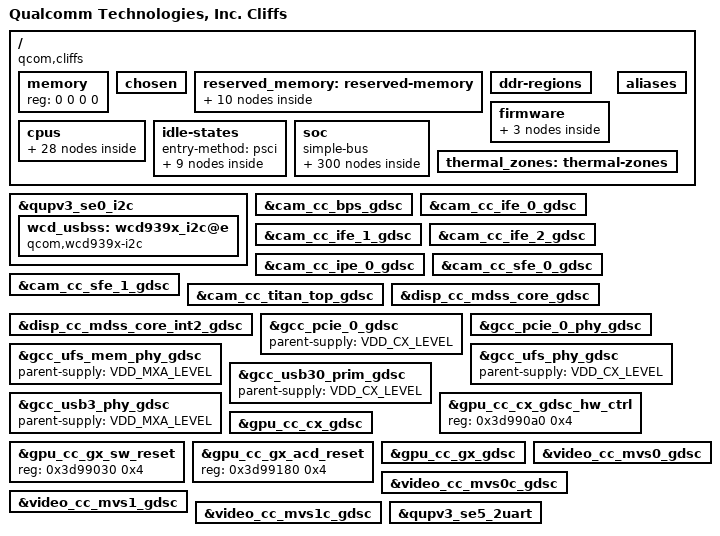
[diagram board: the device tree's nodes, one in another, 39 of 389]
#include <dt-bindings/clock/qcom,camcc-cliffs.h>
#include <dt-bindings/clock/qcom,dispcc-pineapple.h>
#include <dt-bindings/clock/qcom,gcc-cliffs.h>
#include <dt-bindings/clock/qcom,gpucc-cliffs.h>
#include <dt-bindings/clock/qcom,rpmh.h>
#include <dt-bindings/clock/qcom,tcsrcc-pineapple.h>
#include <dt-bindings/clock/qcom,videocc-pineapple.h>
#include <dt-bindings/interrupt-controller/arm-gic.h>
#include <dt-bindings/soc/qcom,ipcc.h>
#include <dt-bindings/soc/qcom,rpmh-rsc.h>
#include <dt-bindings/gpio/gpio.h>
#include <dt-bindings/interconnect/qcom,icc.h>
#include <dt-bindings/interconnect/qcom,cliffs.h>
#include <dt-bindings/spmi/spmi.h>
#include <dt-bindings/regulator/qcom,rpmh-regulator-levels.h>
#include <dt-bindings/power/qcom-aoss-qmp.h>
#include <dt-bindings/clock/qcom,aop-qmp.h>

/ {
	model = "Qualcomm Technologies, Inc. Cliffs";
	compatible = "qcom,cliffs";
	qcom,msm-id = <614 0x10000>;
	interrupt-parent = <&intc>;

	#address-cells = <2>;
	#size-cells = <2>;
	memory { device_type = "memory"; reg = <0 0 0 0>; };

	chosen: chosen {
		bootargs = "loglevel=6 kpti=0 log_buf_len=256K swiotlb=noforce loop.max_part=7 pcie_ports=compat irqaffinity=0-2 cpufreq.default_governor=performance sysctl.kernel.sched_pelt_multiplier=4 kasan=off cgroup.memory=nokmem,nosocket disable_dma32=on kernel.panic_on_rcu_stall=1 fw_devlink.strict=1 service_locator.enable=1 rcupdate.rcu_expedited=1 rcu_nocbs=0-7 no-steal-acc printk.console_no_auto_verbose=0 can.stats_timer=0 ftrace_dump_on_oops firmware_class.path=/vendor/firmware_mnt/image,/vendor/firmware_mnt/image/kiwi,/vendor/vm-system/oemvm/boot,/vendor/vm-system/trustedvm/boot,/vendor/firmware,/vendor/firmware/wlan/qca_cld/kiwi_v2 pci-msm-drv.pcie_sm_regs=0x1D07000,0x1040,0x1048,0x3000,0x1";
		stdout-path = "/soc/qcom,qupv3_0_geni_se@ac0000/qcom,qup_uart@a94000:115200n8";
	};

	reserved_memory: reserved-memory {};

	ddr-regions { };

	firmware: firmware {};

	aliases: aliases {
		serial0 = &qupv3_se5_2uart;
		hsuart0 = &qupv3_se10_4uart;
		mmc1 = &sdhc_2; /* SDC2 SD card slot */
		ufshc1 = &ufshc_mem; /* Embedded UFS Slot */
		i2c2 = &qupv3_se0_i2c;
		i2c4 = &qupv3_se11_i2c;
	};

	cpus {
		#address-cells = <2>;
		#size-cells = <0>;

		CPU0: cpu@0 {
			device_type = "cpu";
			compatible = "qcom,kryo";
			reg = <0x0 0x0>;
			enable-method = "psci";
			cpu-idle-states = <&SILVER_OFF &SILVER_RAIL_OFF>;
			power-domains = <&CPU_PD0>;
			power-domain-names = "psci";
			qcom,freq-domain = <&cpufreq_hw 0>;
			capacity-dmips-mhz = <1024>;
			dynamic-power-coefficient = <100>;
			next-level-cache = <&L2_0>;
			#cooling-cells = <2>;
			L2_0: l2-cache {
			      compatible = "arm,arch-cache";
			      cache-level = <2>;
			      next-level-cache = <&L3_0>;

				L3_0: l3-cache {
					compatible = "arm,arch-cache";
					cache-level = <3>;
				};
			};
		};

		CPU1: cpu@100 {
			device_type = "cpu";
			compatible = "qcom,kryo";
			reg = <0x0 0x100>;
			enable-method = "psci";
			cpu-idle-states = <&SILVER_OFF &SILVER_RAIL_OFF>;
			power-domains = <&CPU_PD1>;
			power-domain-names = "psci";
			qcom,freq-domain = <&cpufreq_hw 0>;
			capacity-dmips-mhz = <1024>;
			dynamic-power-coefficient = <100>;
			next-level-cache = <&L2_0>;
			#cooling-cells = <2>;
		};

		CPU2: cpu@200 {
			device_type = "cpu";
			compatible = "qcom,kryo";
			reg = <0x0 0x200>;
			enable-method = "psci";
			cpu-idle-states = <&SILVER_OFF &SILVER_RAIL_OFF>;
			power-domains = <&CPU_PD2>;
			power-domain-names = "psci";
			qcom,freq-domain = <&cpufreq_hw 0>;
			capacity-dmips-mhz = <1024>;
			dynamic-power-coefficient = <100>;
			next-level-cache = <&L2_2>;
			#cooling-cells = <2>;
			L2_2: l2-cache {
			      compatible = "arm,arch-cache";
			      cache-level = <2>;
			      next-level-cache = <&L3_0>;
			};
		};

		CPU3: cpu@300 {
			device_type = "cpu";
			compatible = "qcom,kryo";
			reg = <0x0 0x300>;
			enable-method = "psci";
			cpu-idle-states = <&GOLD_OFF &GOLD_RAIL_OFF>;
			power-domains = <&CPU_PD3>;
			power-domain-names = "psci";
			qcom,freq-domain = <&cpufreq_hw 1>;
			capacity-dmips-mhz = <1690>;
			dynamic-power-coefficient = <287>;
			next-level-cache = <&L2_3>;
			#cooling-cells = <2>;
			L2_3: l2-cache {
			      compatible = "arm,arch-cache";
			      cache-level = <2>;
			      next-level-cache = <&L3_0>;
			};
		};

		CPU4: cpu@400 {
			device_type = "cpu";
			compatible = "qcom,kryo";
			reg = <0x0 0x400>;
			enable-method = "psci";
			cpu-idle-states = <&GOLD_OFF &GOLD_RAIL_OFF>;
			power-domains = <&CPU_PD4>;
			power-domain-names = "psci";
			qcom,freq-domain = <&cpufreq_hw 1>;
			capacity-dmips-mhz = <1690>;
			dynamic-power-coefficient = <287>;
			next-level-cache = <&L2_4>;
			#cooling-cells = <2>;
			L2_4: l2-cache {
			      compatible = "arm,arch-cache";
			      cache-level = <2>;
			      next-level-cache = <&L3_0>;
			};
		};

		CPU5: cpu@500 {
			device_type = "cpu";
			compatible = "qcom,kryo";
			reg = <0x0 0x500>;
			enable-method = "psci";
			cpu-idle-states = <&GOLD_OFF &GOLD_RAIL_OFF>;
			power-domains = <&CPU_PD5>;
			power-domain-names = "psci";
			qcom,freq-domain = <&cpufreq_hw 1>;
			capacity-dmips-mhz = <1690>;
			dynamic-power-coefficient = <287>;
			next-level-cache = <&L2_5>;
			#cooling-cells = <2>;
			L2_5: l2-cache {
			      compatible = "arm,arch-cache";
			      cache-level = <2>;
			      next-level-cache = <&L3_0>;
			};
		};

		CPU6: cpu@600 {
			device_type = "cpu";
			compatible = "qcom,kryo";
			reg = <0x0 0x600>;
			enable-method = "psci";
			cpu-idle-states = <&GOLD_OFF &GOLD_RAIL_OFF>;
			power-domains = <&CPU_PD6>;
			power-domain-names = "psci";
			qcom,freq-domain = <&cpufreq_hw 1>;
			capacity-dmips-mhz = <1690>;
			dynamic-power-coefficient = <287>;
			next-level-cache = <&L2_6>;
			#cooling-cells = <2>;
			L2_6: l2-cache {
			      compatible = "arm,arch-cache";
			      cache-level = <2>;
			      next-level-cache = <&L3_0>;
			};
		};

		CPU7: cpu@700 {
			device_type = "cpu";
			compatible = "qcom,kryo";
			reg = <0x0 0x700>;
			enable-method = "psci";
			cpu-idle-states = <&GOLD_PLUS_OFF &GOLD_PLUS_RAIL_OFF>;
			power-domains = <&CPU_PD7>;
			power-domain-names = "psci";
			qcom,freq-domain = <&cpufreq_hw 2>;
			capacity-dmips-mhz = <1843>;
			dynamic-power-coefficient = <664>;
			next-level-cache = <&L2_7>;
			#cooling-cells = <2>;
			L2_7: l2-cache {
			      compatible = "arm,arch-cache";
			      cache-level = <2>;
			      next-level-cache = <&L3_0>;
			};
		};

		cpu-map {
			cluster0 {
				core0 {
					cpu = <&CPU0>;
				};

				core1 {
					cpu = <&CPU1>;
				};

				core2 {
					cpu = <&CPU2>;
				};
			};

			cluster1 {
				core0 {
					cpu = <&CPU3>;
				};

				core1 {
					cpu = <&CPU4>;
				};

				core2 {
					cpu = <&CPU5>;
				};

				core3 {
					cpu = <&CPU6>;
				};
			};

			cluster2 {
				core0 {
					cpu = <&CPU7>;
				};
			};
		};
	};

	idle-states {
		entry-method = "psci";

		SILVER_OFF: silver-c3 {  /* C3 */
			compatible = "arm,idle-state";
			idle-state-name = "pc";
			entry-latency-us = <250>;
			exit-latency-us = <900>;
			min-residency-us = <3200>;
			arm,psci-suspend-param = <0x40000003>;
			local-timer-stop;
		};

		SILVER_RAIL_OFF: silver-cluster0-c4 { /* C4 */
			compatible = "arm,idle-state";
			idle-state-name = "rail-pc";
			entry-latency-us = <550>;
			exit-latency-us = <750>;
			min-residency-us = <6700>;
			arm,psci-suspend-param = <0x40000004>;
			local-timer-stop;
		};

		GOLD_OFF: gold-c3 {  /* C3 */
			compatible = "arm,idle-state";
			idle-state-name = "pc";
			entry-latency-us = <400>;
			exit-latency-us = <1100>;
			min-residency-us = <4011>;
			arm,psci-suspend-param = <0x40000003>;
			local-timer-stop;
		};

		GOLD_RAIL_OFF: gold-cluster1-c4 { /* C4 */
			compatible = "arm,idle-state";
			idle-state-name = "rail-pc";
			entry-latency-us = <550>;
			exit-latency-us = <1050>;
			min-residency-us = <7951>;
			arm,psci-suspend-param = <0x40000004>;
			local-timer-stop;
		};

		GOLD_PLUS_OFF: gold-plus-c3 {  /* C3 */
			compatible = "arm,idle-state";
			idle-state-name = "pc";
			entry-latency-us = <450>;
			exit-latency-us = <1200>;
			min-residency-us = <6230>;
			arm,psci-suspend-param = <0x40000003>;
			local-timer-stop;
		};

		GOLD_PLUS_RAIL_OFF: gold-plus-cluster3-c4 { /* C4 */
			compatible = "arm,idle-state";
			idle-state-name = "rail-pc";
			entry-latency-us = <500>;
			exit-latency-us = <1350>;
			min-residency-us = <7480>;
			arm,psci-suspend-param = <0x40000004>;
			local-timer-stop;
		};

		CLUSTER_PWR_DN: cluster-d4 { /* D4 */
			compatible = "domain-idle-state";
			idle-state-name = "l3-off";
			entry-latency-us = <750>;
			exit-latency-us = <2350>;
			min-residency-us = <9144>;
			arm,psci-suspend-param = <0x41000044>;
		};

		CX_RET: cx-ret { /* Cx Ret */
			compatible = "domain-idle-state";
			idle-state-name = "cx-ret";
			entry-latency-us = <1561>;
			exit-latency-us = <2801>;
			min-residency-us = <8550>;
			arm,psci-suspend-param = <0x41001344>;
		};

		APSS_OFF: cluster-e3 { /* E3 */
			compatible = "domain-idle-state";
			idle-state-name = "llcc-off";
			entry-latency-us = <2800>;
			exit-latency-us = <4400>;
			min-residency-us = <10150>;
			arm,psci-suspend-param = <0x4100b344>;
		};
	};

	soc: soc { };

	thermal_zones: thermal-zones {
	};
};

#include "cliffs-coresight.dtsi"
#include "cliffs-debug.dtsi"

&soc {
	#address-cells = <1>;
	#size-cells = <1>;
	ranges = <0 0 0 0xffffffff>;
	compatible = "simple-bus";

	disp_rdump_region@d5100000 {
	};

	dsi_pll_codes {
	};

	slimbam: bamdma@6C04000 {
		compatible = "qcom,bam-v1.7.0";
		qcom,controlled-remotely;
		reg = <0x6C04000 0x20000>, <0x6C8F000 0x1000>;
		reg-names = "bam", "bam_remote_mem";
		num-channels  = <31>;
		interrupts = <0 164 IRQ_TYPE_LEVEL_HIGH>;
		#dma-cells = <1>;
		qcom,ee = <1>;
		qcom,num-ees = <2>;
	};

	slim_msm: slim@6C40000 {
		compatible = "qcom,slim-ngd-v1.5.0";
		reg = <0x6C40000 0x2C000>, <0x6C8E000 0x1000>;
		reg-names = "ctrl", "slimbus_remote_mem";
		interrupts = <0 163 IRQ_TYPE_LEVEL_HIGH>;
		qcom,apps-ch-pipes = <0x0>;
		qcom,ea-pc = <0x4f0>;
		dmas = <&slimbam 3>, <&slimbam 4>;
		dma-names = "rx", "tx";
		#address-cells = <1>;
		#size-cells = <0>;
		status = "disabled";
	};

	intc: interrupt-controller@17100000 {
		compatible = "arm,gic-v3";
		#interrupt-cells = <3>;
		interrupt-controller;
		ranges;
		#redistributor-regions = <1>;
		redistributor-stride = <0x0 0x40000>;
		reg = <0x17100000 0x10000>,	/* GICD */
		      <0x17180000 0x200000>;	/* GICR * 8 */
		interrupts = <GIC_PPI 9 IRQ_TYPE_LEVEL_HIGH>;

		#address-cells = <1>;
		#size-cells = <1>;
		gic_its: msi-controller@17140000 {
			compatible = "arm,gic-v3-its";
			msi-controller;
			#msi-cells = <1>;
			reg = <0x17140000 0x20000>;
		};
	};

	arch_timer: timer {
		compatible = "arm,armv8-timer";
		interrupts = <GIC_PPI 13 (GIC_CPU_MASK_SIMPLE(8) | IRQ_TYPE_LEVEL_LOW)>,
			     <GIC_PPI 14 (GIC_CPU_MASK_SIMPLE(8) | IRQ_TYPE_LEVEL_LOW)>,
			     <GIC_PPI 11 (GIC_CPU_MASK_SIMPLE(8) | IRQ_TYPE_LEVEL_LOW)>,
			     <GIC_PPI 12 (GIC_CPU_MASK_SIMPLE(8) | IRQ_TYPE_LEVEL_LOW)>;
		clock-frequency = <19200000>;
	};

	memtimer: timer@17420000 {
		#address-cells = <1>;
		#size-cells = <1>;
		ranges;
		compatible = "arm,armv7-timer-mem";
		reg = <0x17420000 0x1000>;
		clock-frequency = <19200000>;

		frame@17421000 {
			frame-number = <0>;
			interrupts = <GIC_SPI 8 IRQ_TYPE_LEVEL_HIGH>,
				     <GIC_SPI 6 IRQ_TYPE_LEVEL_HIGH>;
			reg = <0x17421000 0x1000>,
			      <0x17422000 0x1000>;
		};

		frame@17423000 {
			frame-number = <1>;
			interrupts = <GIC_SPI 9 IRQ_TYPE_LEVEL_HIGH>;
			reg = <0x17423000 0x1000>;
			status = "disabled";
		};

		frame@17425000 {
			frame-number = <2>;
			interrupts = <GIC_SPI 10 IRQ_TYPE_LEVEL_HIGH>;
			reg = <0x17425000 0x1000>;
			status = "disabled";
		};

		frame@17427000 {
			frame-number = <3>;
			interrupts = <GIC_SPI 11 IRQ_TYPE_LEVEL_HIGH>;
			reg = <0x17427000 0x1000>;
			status = "disabled";
		};

		frame@17429000 {
			frame-number = <4>;
			interrupts = <GIC_SPI 12 IRQ_TYPE_LEVEL_HIGH>;
			reg = <0x17429000 0x1000>;
			status = "disabled";
		};

		frame@1742b000 {
			frame-number = <5>;
			interrupts = <GIC_SPI 13 IRQ_TYPE_LEVEL_HIGH>;
			reg = <0x1742b000 0x1000>;
			status = "disabled";
		};

		frame@1742d000 {
			frame-number = <6>;
			interrupts = <GIC_SPI 14 IRQ_TYPE_LEVEL_HIGH>;
			reg = <0x1742d000 0x1000>;
			status = "disabled";
		};
	};

	apps_rsc: rsc@17a00000 {
		label = "apps_rsc";
		compatible = "qcom,rpmh-rsc";
		reg = <0x17a00000 0x10000>,
		      <0x17a10000 0x10000>,
		      <0x17a20000 0x10000>;
		reg-names = "drv-0", "drv-1", "drv-2";
		qcom,drv-count = <3>;
		interrupts = <GIC_SPI 3 IRQ_TYPE_LEVEL_HIGH>,
			     <GIC_SPI 4 IRQ_TYPE_LEVEL_HIGH>,
			     <GIC_SPI 5 IRQ_TYPE_LEVEL_HIGH>;
		power-domains = <&CLUSTER_PD>;

		apps_rsc_drv2: drv@2 {
			qcom,drv-id = <2>;
			qcom,tcs-offset = <0xd00>;
			channel@0 {
				qcom,tcs-config = <ACTIVE_TCS    3>,
						  <SLEEP_TCS     2>,
						  <WAKE_TCS      2>,
						  <CONTROL_TCS   0>,
						  <FAST_PATH_TCS 1>;
			};

			apps_bcm_voter: bcm_voter {
				compatible = "qcom,bcm-voter";
			};

			rpmhcc: clock-controller {
				compatible = "qcom,cliffs-rpmh-clk";
				#clock-cells = <1>;
			};

			dcvs_fp: qcom,dcvs-fp {
				compatible = "qcom,dcvs-fp";
				qcom,ddr-bcm-name = "MC4";
				qcom,llcc-bcm-name = "SH5";
			};
		};
	};

	pdc: interrupt-controller@b220000 {
		compatible = "qcom,cliffs-pdc", "qcom,pdc";
		reg = <0xb220000 0x10000>, <0x174000f0 0x64>;
		qcom,pdc-ranges = <0 480 94>, <94 609 31>, <125 63 1>,
				  <126 716 12>, <138 251 5>, <143 244 4>;
		#interrupt-cells = <2>;
		interrupt-parent = <&intc>;
		interrupt-controller;
	};

	pcie_pdc: pdc@b350000 {
		compatible = "qcom,cliffs-pcie-pdc", "qcom,pcie-pdc";
		reg = <0xb350000 0x20000>;
	};

	cache_cont: cache-controller@25000000 {
		label = "cache_cont";
		compatible = "qcom,cliffs-llcc", "qcom,llcc-v50";
		reg = <0x25000000 0x800000> , <0x25800000 0x200000>;
		reg-names = "llcc_base", "llcc_broadcast_base";
		interrupts = <GIC_SPI 266 IRQ_TYPE_LEVEL_HIGH>;
		cap-based-alloc-and-pwr-collapse;

		llcc-perfmon {
			compatible = "qcom,llcc-perfmon";
			clocks = <&aoss_qmp QDSS_CLK>;
			clock-names = "qdss_clk";
		};
	};

	cluster-device {
		compatible = "qcom,lpm-cluster-dev";
		power-domains = <&CLUSTER_PD>;
	};

	cam_rsc: rsc@add4000 {
		label = "cam_rsc";
		compatible = "qcom,rpmh-rsc";
		reg = <0xadd4000 0x1000>,
		      <0xadd5000 0x1000>,
		      <0xadd6000 0x1000>;
		reg-names = "drv-0", "drv-1", "drv-2";
		qcom,drv-count = <3>;
		qcom,hw-channel;
		interrupts = <GIC_SPI 368 IRQ_TYPE_LEVEL_HIGH>,
			     <GIC_SPI 369 IRQ_TYPE_LEVEL_HIGH>,
			     <GIC_SPI 370 IRQ_TYPE_LEVEL_HIGH>;
		clocks = <&camcc CAM_CC_DRV_AHB_CLK>;

		cam_rsc_drv0: drv@0 {
			qcom,drv-id = <0>;
			qcom,tcs-offset = <0x520>;
			channel@0 {
				qcom,tcs-config = <ACTIVE_TCS    0>,
						  <WAKE_TCS      1>,
						  <SLEEP_TCS     1>,
						  <CONTROL_TCS   0>,
						  <FAST_PATH_TCS 0>;
			};

			channel@1 {
				qcom,tcs-config = <ACTIVE_TCS    0>,
						  <WAKE_TCS      1>,
						  <SLEEP_TCS     1>,
						  <CONTROL_TCS   0>,
						  <FAST_PATH_TCS 0>;
			};

			cam_bcm_voter0: bcm_voter {
				compatible = "qcom,bcm-voter";
				qcom,no-amc;
			};
		};

		cam_rsc_drv1: drv@1 {
			qcom,drv-id = <1>;
			qcom,tcs-offset = <0x520>;
			channel@0 {
				qcom,tcs-config = <ACTIVE_TCS    0>,
						  <WAKE_TCS      1>,
						  <SLEEP_TCS     1>,
						  <CONTROL_TCS   0>,
						  <FAST_PATH_TCS 0>;
			};

			channel@1 {
				qcom,tcs-config = <ACTIVE_TCS    0>,
						  <WAKE_TCS      1>,
						  <SLEEP_TCS     1>,
						  <CONTROL_TCS   0>,
						  <FAST_PATH_TCS 0>;
			};

			cam_bcm_voter1: bcm_voter {
				compatible = "qcom,bcm-voter";
				qcom,no-amc;
			};
		};

		cam_rsc_drv2: drv@2 {
			qcom,drv-id = <2>;
			qcom,tcs-offset = <0x520>;
			channel@0 {
				qcom,tcs-config = <ACTIVE_TCS    0>,
						  <WAKE_TCS      1>,
						  <SLEEP_TCS     1>,
						  <CONTROL_TCS   0>,
						  <FAST_PATH_TCS 0>;
			};

			channel@1 {
				qcom,tcs-config = <ACTIVE_TCS    0>,
						  <WAKE_TCS      1>,
						  <SLEEP_TCS     1>,
						  <CONTROL_TCS   0>,
						  <FAST_PATH_TCS 0>;
			};

			cam_bcm_voter2: bcm_voter {
				compatible = "qcom,bcm-voter";
				qcom,no-amc;
			};
		};
	};

	cpuss-sleep-stats@17800054 {
		compatible = "qcom,cpuss-sleep-stats";
		reg = <0x17800054 0x4>, <0x17810054 0x4>, <0x17820054 0x4>,
		      <0x17830054 0x4>, <0x17840054 0x4>, <0x17850054 0x4>,
		      <0x17860054 0x4>, <0x17870054 0x4>, <0x178b0098 0x4>,
		      <0x178c0000 0x10000>;
		reg-names = "seq_lpm_cntr_cfg_cpu0", "seq_lpm_cntr_cfg_cpu1",
			    "seq_lpm_cntr_cfg_cpu2", "seq_lpm_cntr_cfg_cpu3",
			    "seq_lpm_cntr_cfg_cpu4", "seq_lpm_cntr_cfg_cpu5",
			    "seq_lpm_cntr_cfg_cpu6", "seq_lpm_cntr_cfg_cpu7",
			    "l3_seq_lpm_cntr_cfg", "apss_seq_mem_base";
		num-cpus = <8>;
	};

	sys-pm-vx@c320000 {
		compatible = "qcom,sys-pm-violators", "qcom,sys-pm-cliffs";
		reg = <0xc320000 0x0400>;
		qcom,qmp = <&aoss_qmp>;
	};

	disp_rsc: rsc@af20000 {
		label = "disp_rsc";
		compatible = "qcom,rpmh-rsc";
		reg = <0xaf20000 0x10000>;
		reg-names = "drv-0";
		qcom,drv-count = <1>;
		interrupts = <GIC_SPI 129 IRQ_TYPE_LEVEL_HIGH>;
		clocks = <&dispcc DISP_CC_MDSS_RSCC_AHB_CLK>;

		disp_rsc_drv0: drv@0 {
			qcom,drv-id = <0>;
			qcom,tcs-offset = <0x1c00>;
			channel@0 {
				qcom,tcs-config = <ACTIVE_TCS    0>,
						  <SLEEP_TCS     1>,
						  <WAKE_TCS      1>,
						  <CONTROL_TCS   0>,
						  <FAST_PATH_TCS 0>;
			};

			disp_bcm_voter: bcm_voter {
				compatible = "qcom,bcm-voter";
				qcom,tcs-wait = <QCOM_ICC_TAG_AMC>;
			};
		};
	};

	cam_crm: crm@add7000 {
		label = "cam_crm";
		compatible = "qcom,cam-crm";
		reg = <0xadd7000 0x2000>, <0xadd9800 0x800>, <0xadda000 0x2000>, <0xadd9000 0x800>;
		reg-names = "base", "crm_b", "crm_c", "crm_v";
		interrupts = <GIC_SPI 121 IRQ_TYPE_EDGE_RISING>;
		interrupt-names = "cam_crm";
		clocks = <&camcc CAM_CC_DRV_AHB_CLK>;
		qcom,hw-drv-ids = <0 1 2>;
		qcom,sw-drv-ids = <0>;
	};

	pcie_crm: crm@1d01000 {
		label = "pcie_crm";
		compatible = "qcom,pcie-crm";
		reg = <0x1d01000 0x3000>, <0x1d04800 0x800>, <0x1d05000 0x2000>, <0x1d04000 0x800>;
		reg-names = "base", "crm_b", "crm_c", "crm_v";
		interrupts = <GIC_SPI 248 IRQ_TYPE_EDGE_RISING>;
		interrupt-names = "pcie_crm";
		clocks = <&pcie_0_pipe_clk>;
		qcom,hw-drv-ids = <0>;
		qcom,sw-drv-ids = <0>;
	};

	sram@c3f0000 {
		compatible = "qcom,rpmh-stats-v4";
		reg = <0x0c3f0000 0x400>;
		qcom,qmp = <&aoss_qmp>;
		ss-name = "modem", "adsp", "adsp_island",
			  "cdsp", "apss", "wpss";
	};

	tlmm: pinctrl@f000000 {
		compatible = "qcom,cliffs-pinctrl";
		reg = <0x0F000000 0x1000000>;
		interrupts = <GIC_SPI 208 IRQ_TYPE_LEVEL_HIGH>;
		gpio-controller;
		#gpio-cells = <2>;
		interrupt-controller;
		#interrupt-cells = <2>;
		wakeup-parent = <&pdc>;
		qcom,gpios-reserved = <8 9 10 11 56 57 58 59 60>;
	};

	spmi_bus: spmi0_bus: qcom,spmi@c42d000 {
		compatible = "qcom,spmi-pmic-arb";
		reg = <0xc42d000 0x4000>,
		      <0xc400000 0x3000>,
		      <0xc500000 0x400000>,
		      <0xc440000 0x80000>,
		      <0xc4c0000 0x10000>;
		reg-names = "cnfg", "core", "chnls", "obsrvr", "intr";
		interrupts-extended = <&pdc 1 IRQ_TYPE_LEVEL_HIGH>;
		interrupt-names = "periph_irq";
		interrupt-controller;
		#interrupt-cells = <4>;
		#address-cells = <2>;
		#size-cells = <0>;
		cell-index = <0>;
		qcom,channel = <0>;
		qcom,ee = <0>;
		qcom,bus-id = <0>;
	};

	spmi1_bus: qcom,spmi@c432000 {
		compatible = "qcom,spmi-pmic-arb";
		reg = <0xc432000 0x4000>,
		      <0xc400000 0x3000>,
		      <0xc500000 0x400000>,
		      <0xc440000 0x80000>,
		      <0xc4d0000 0x10000>;
		reg-names = "cnfg", "core", "chnls", "obsrvr", "intr";
		interrupts-extended = <&pdc 3 IRQ_TYPE_LEVEL_HIGH>;
		interrupt-names = "periph_irq";
		interrupt-controller;
		#interrupt-cells = <4>;
		#address-cells = <2>;
		#size-cells = <0>;
		cell-index = <0>;
		qcom,channel = <0>;
		qcom,ee = <0>;
		qcom,bus-id = <1>;
		depends-on-supply = <&spmi0_bus>;
	};

	spmi0_debug_bus: qcom,spmi-debug@10b14000 {
		compatible = "qcom,spmi-pmic-arb-debug";
		reg = <0x10b14000 0x60>, <0x221c8784 0x4>;
		reg-names = "core", "fuse";
		clocks = <&aoss_qmp>;
		clock-names = "core_clk";
		qcom,fuse-enable-bit = <18>;
		#address-cells = <2>;
		#size-cells = <0>;
		depends-on-supply = <&spmi1_bus>;

		qcom,pmk8550-debug@0 {
			compatible = "qcom,spmi-pmic";
			reg = <0 SPMI_USID>;
			#address-cells = <2>;
			#size-cells = <0>;
			qcom,can-sleep;
		};

		qcom,pmxr2230-debug@1 {
			compatible = "qcom,spmi-pmic";
			reg = <1 SPMI_USID>;
			#address-cells = <2>;
			#size-cells = <0>;
			qcom,can-sleep;
		};

		qcom,pm8550vs-debug@2 {
			compatible = "qcom,spmi-pmic";
			reg = <2 SPMI_USID>;
			#address-cells = <2>;
			#size-cells = <0>;
			qcom,can-sleep;
		};

		qcom,pm8550ve-debug@3 {
			compatible = "qcom,spmi-pmic";
			reg = <3 SPMI_USID>;
			#address-cells = <2>;
			#size-cells = <0>;
			qcom,can-sleep;
		};

		qcom,pmr735a-debug@4 {
			compatible = "qcom,spmi-pmic";
			reg = <4 SPMI_USID>;
			#address-cells = <2>;
			#size-cells = <0>;
			qcom,can-sleep;
		};

		qcom,pmg1110-debug@8 {
			compatible = "qcom,spmi-pmic";
			reg = <8 SPMI_USID>;
			#address-cells = <2>;
			#size-cells = <0>;
			qcom,can-sleep;
		};

		qcom,pm8010-debug@c {
			compatible = "qcom,spmi-pmic";
			reg = <12 SPMI_USID>;
			#address-cells = <2>;
			#size-cells = <0>;
			qcom,can-sleep;
		};

		qcom,pm8010-debug@d {
			compatible = "qcom,spmi-pmic";
			reg = <13 SPMI_USID>;
			#address-cells = <2>;
			#size-cells = <0>;
			qcom,can-sleep;
		};
	};

	qcom,msm-imem@14680000 {
		compatible = "qcom,msm-imem";
		reg = <0x14680000 0x1000>;
		ranges = <0x0 0x14680000 0x1000>;
		#address-cells = <1>;
		#size-cells = <1>;

		mem_dump_table@10 {
			compatible = "qcom,msm-imem-mem_dump_table";
			reg = <0x10 0x8>;
		};

		restart_reason@65c {
			compatible = "qcom,msm-imem-restart_reason";
			reg = <0x65c 0x4>;
		};

		dload_type@1c {
			compatible = "qcom,msm-imem-dload-type";
			reg = <0x1c 0x4>;
		};

		boot_stats@6b0 {
			compatible = "qcom,msm-imem-boot_stats";
			reg = <0x6b0 0x20>;
		};

		kaslr_offset@6d0 {
			compatible = "qcom,msm-imem-kaslr_offset";
			reg = <0x6d0 0xc>;
		};

		pil@94c {
			compatible = "qcom,pil-reloc-info";
			reg = <0x94c 0xc8>;
		};

		pil@6dc {
			compatible = "qcom,msm-imem-pil-disable-timeout";
			reg = <0x6dc 0x4>;
		};

		diag_dload@c8 {
			compatible = "qcom,msm-imem-diag-dload";
			reg = <0xc8 0xc8>;
		};

		modem_dsm@c98 {
			compatible = "qcom,msm-imem-mss-dsm";
			reg = <0xc98 0x10>;
		};
	};

	dload_mode {
		compatible = "qcom,dload-mode";
	};

	mini_dump_mode {
		compatible = "qcom,minidump";
		status = "ok";
	};

	va_mini_dump {
		compatible = "qcom,va-minidump";
		memory-region = <&va_md_mem>;
		status = "ok";
	};

	cpu_pmu: cpu-pmu {
		compatible = "arm,armv8-pmuv3";
		interrupts = <GIC_PPI 7 IRQ_TYPE_LEVEL_HIGH>;
	};

	qcom,msm-cdsp-loader {
		compatible = "qcom,cdsp-loader";
		qcom,proc-img-to-load = "cdsp";
		qcom,rproc-handle = <&cdsp_pas>;
	};

	qcom,msm-adsprpc-mem {
		compatible = "qcom,msm-adsprpc-mem-region";
		memory-region = <&adsp_mem_heap>;
		restrict-access;
	};

	qcom,chd {
		compatible = "qcom,core-hang-detect";
		label = "core";
		qcom,chd-percpu-info = <&CPU0 0x17800058 0x17800060>,
					<&CPU1 0x17810058 0x17810060>,
					<&CPU2 0x17820058 0x17820060>,
					<&CPU3 0x17830058 0x17830060>,
					<&CPU4 0x17840058 0x17840060>,
					<&CPU5 0x17850058 0x17850060>,
					<&CPU6 0x17860058 0x17860060>,
					<&CPU7 0x17870058 0x17870060>;
	};

	trust_ui_vm_vblk0_ring: trust_ui_vm_vblk0_ring {
		size = <0x4000>;
		gunyah-label = <0x11>;
	};

	trust_ui_vm_vblk1_ring: trust_ui_vm_vblk1_ring {
		size = <0x4000>;
		gunyah-label = <0x10>;
	};

	trust_ui_vm_swiotlb: trust_ui_vm_swiotlb {
		size = <0x100000>;
		gunyah-label = <0x12>;
	};

	trust_ui_vm: qcom,trust_ui_vm {
		vm_name = "trustedvm";
		shared-buffers-size = <0x108000>;
		shared-buffers = <&trust_ui_vm_vblk0_ring &trust_ui_vm_vblk1_ring &trust_ui_vm_swiotlb>;
	};

	trust_ui_vm_virt_be0: trust_ui_vm_virt_be0@11 {
		qcom,vm = <&trust_ui_vm>;
		qcom,label = <0x11>;
	};

	trust_ui_vm_virt_be1: trust_ui_vm_virt_be1@10 {
		qcom,vm = <&trust_ui_vm>;
		qcom,label = <0x10>;
	};

	gh-secure-vm-loader@0 {
		compatible = "qcom,gh-secure-vm-loader";
		qcom,pas-id = <28>;
		qcom,vmid = <45>;
		qcom,firmware-name = "trustedvm";
		qcom,keep-running;
		memory-region = <&trust_ui_vm_mem &vm_comm_mem>;
		virtio-backends = <&trust_ui_vm_virt_be0 &trust_ui_vm_virt_be1>;
	};

	qcom,qrtr-gunyah-tuivm {
		compatible = "qcom,qrtr-gunyah";
		qcom,master;
		gunyah-label = <3>;
		peer-name = <2>;
	};

	gh-secure-vm-loader@2 {
		compatible = "qcom,gh-secure-vm-loader";
		qcom,pas-id = <35>;
		qcom,vmid = <50>;
		qcom,firmware-name = "cpusys_vm";
		memory-region = <&cpusys_vm_mem>;
		ext-region = <&chipinfo_mem>;
		ext-label = <0x7>;
	};

	oem_vm_vblk0_ring: oem_vm_vblk0_ring {
		size = <0x4000>;
		gunyah-label = <0x13>;
	};

	oem_vm_swiotlb: oem_vm_swiotlb {
		size = <0x100000>;
		gunyah-label = <0x14>;
	};

	oem_vm: qcom,oem_vm {
		vm_name = "oemvm";
		shared-buffers-size = <0x104000>;
		shared-buffers = <&oem_vm_vblk0_ring &oem_vm_swiotlb>;
	};

	oem_vm_virt_be0: oem_vm_virt_be0@13 {
		qcom,vm = <&oem_vm>;
		qcom,label = <0x13>;
	};

	gh-secure-vm-loader@1 {
		compatible = "qcom,gh-secure-vm-loader";
		qcom,pas-id = <34>;
		qcom,vmid = <49>;
		qcom,firmware-name = "oemvm";
		memory-region = <&oem_vm_mem &vm_comm_mem>;
		virtio-backends = <&oem_vm_virt_be0>;
	};

	qcom,qrtr-gunyah-oemvm {
		compatible = "qcom,qrtr-gunyah";
		qcom,master;
		gunyah-label = <8>;
		peer-name = <4>;
	};

	dmesg-dump {
		compatible = "qcom,dmesg-dump";
		qcom,primary-vm;
		gunyah-label = <7>;
		peer-name = <2>;
		memory-region = <&vm_comm_mem>;
		shared-buffer-size = <0x1000>;
	};

	qcom,gunyah-panic-notifier {
		compatible = "qcom,gh-panic-notifier";
		qcom,primary-vm;
		gunyah-label = <9>;
		peer-name = <2>;
		memory-region = <&vm_comm_mem>;
		shared-buffer-size = <0x1000>;
	};

	tlmm-vm-mem-access {
		compatible = "qcom,tlmm-vm-mem-access";
		qcom,master;
		tlmm-vm-gpio-list = <&tlmm 16 0 &tlmm 17 0 &tlmm 18 0 &tlmm 19 0
				     &tlmm 44 0 &tlmm 45 0 &tlmm 46 0 &tlmm 47 0
				     &tlmm 128 0 &tlmm 129 0 &tlmm 131 0 &tlmm 29 0
				     &tlmm 177 0 &tlmm 54 0 &tlmm 77 0 &tlmm 78 0>;
	};

	tlmm-vm-test {
		compatible = "qcom,tlmm-vm-test";
		qcom,master;
		tlmm-vm-gpio-list = <&tlmm 16 0 &tlmm 17 0 &tlmm 18 0 &tlmm 19 0
				     &tlmm 44 0 &tlmm 45 0 &tlmm 46 0 &tlmm 47 0
				     &tlmm 128 0 &tlmm 129 0 &tlmm 131 0 &tlmm 29 0
				     &tlmm 177 0 &tlmm 54 0 &tlmm 77 0 &tlmm 78 0>;
	};

	qcom,test-dbl-tuivm {
		compatible = "qcom,gh-dbl";
		qcom,label = <0x4>;
	};

	qcom,test-dbl-oemvm {
		compatible = "qcom,gh-dbl";
		qcom,label = <0x5>;
	};

	qcom,test-msgq-tuivm {
		compatible = "qcom,gh-msgq-test";
		gunyah-label = <4>;
		qcom,primary;
	};

	qcom,test-msgq-oemvm {
		compatible = "qcom,gh-msgq-test";
		gunyah-label = <5>;
		qcom,primary;
	};

	qcom,gh-qtimer@17425000 {
		compatible = "qcom,gh-qtmr";
		reg = <0x17425000 0x1000>;
		reg-names = "qtmr-base";
		interrupts = <GIC_SPI 10 IRQ_TYPE_LEVEL_HIGH>;
		interrupt-names = "qcom,qtmr-intr";
		qcom,primary;
	};

	clocks {
		xo_board: xo_board {
			compatible = "fixed-clock";
			clock-frequency = <76800000>;
			clock-output-names = "xo_board";
			#clock-cells = <0>;
		};

		sleep_clk: sleep_clk {
			compatible = "fixed-clock";
			clock-frequency = <32000>;
			clock-output-names = "sleep_clk";
			#clock-cells = <0>;
		};

		pcie_0_pipe_clk: pcie_0_pipe_clk {
			compatible = "fixed-clock";
			clock-frequency = <1000>;
			clock-output-names = "pcie_0_pipe_clk";
			#clock-cells = <0>;
		};

		ufs_phy_rx_symbol_0_clk: ufs_phy_rx_symbol_0_clk {
			compatible = "fixed-clock";
			clock-frequency = <1000>;
			clock-output-names = "ufs_phy_rx_symbol_0_clk";
			#clock-cells = <0>;
		};

		ufs_phy_rx_symbol_1_clk: ufs_phy_rx_symbol_1_clk {
			compatible = "fixed-clock";
			clock-frequency = <1000>;
			clock-output-names = "ufs_phy_rx_symbol_1_clk";
			#clock-cells = <0>;
		};

		ufs_phy_tx_symbol_0_clk: ufs_phy_tx_symbol_0_clk {
			compatible = "fixed-clock";
			clock-frequency = <1000>;
			clock-output-names = "ufs_phy_tx_symbol_0_clk";
			#clock-cells = <0>;
		};

		usb3_phy_wrapper_gcc_usb30_pipe_clk: usb3_phy_wrapper_gcc_usb30_pipe_clk {
			compatible = "fixed-clock";
			clock-frequency = <1000>;
			clock-output-names = "usb3_phy_wrapper_gcc_usb30_pipe_clk";
			#clock-cells = <0>;
		};
	};

	camcc_crmc: syscon@adda000 {
		compatible = "syscon";
		reg = <0xadda000 0x2000>;
	};

	camcc: clock-controller@ade0000 {
		compatible = "qcom,cliffs-camcc", "syscon";
		reg = <0xade0000 0x20000>;
		reg-name = "cc_base";
		vdd_mm-supply = <&VDD_MM_LEVEL>;
		vdd_mx-supply = <&VDD_MXA_LEVEL>;
		vdd_mxc-supply = <&VDD_MXC_LEVEL>;
		clocks = <&rpmhcc RPMH_CXO_CLK>, <&rpmhcc RPMH_CXO_CLK_A>,
			<&sleep_clk>, <&gcc GCC_CAMERA_AHB_CLK>;
		clock-names = "bi_tcxo", "bi_tcxo_ao",
			"sleep_clk", "iface";
		qcom,cam_crm-crmc = <&camcc_crmc>;
		#clock-cells = <1>;
		#reset-cells = <1>;
	};

	dispcc: clock-controller@af00000 {
		compatible = "qcom,cliffs-dispcc", "syscon";
		reg = <0xaf00000 0x20000>;
		reg-name = "cc_base";
		vdd_mm-supply = <&VDD_MM_LEVEL>;
		vdd_mxa-supply = <&VDD_MXA_LEVEL>;
		clocks = <&rpmhcc RPMH_CXO_CLK>, <&rpmhcc RPMH_CXO_CLK_A>,
			<&sleep_clk>, <&gcc GCC_DISP_AHB_CLK>;
		clock-names = "bi_tcxo", "bi_tcxo_ao",
			"sleep_clk", "iface";
		#clock-cells = <1>;
		#reset-cells = <1>;
	};

	gcc: clock-controller@100000 {
		compatible = "qcom,cliffs-gcc", "syscon";
		reg = <0x100000 0x1f4200>;
		reg-name = "cc_base";
		vdd_cx-supply = <&VDD_CX_LEVEL>;
		vdd_mx-supply = <&VDD_MXA_LEVEL>;
		clocks = <&rpmhcc RPMH_CXO_CLK>, <&pcie_0_pipe_clk>,
			<&sleep_clk>, <&ufs_phy_rx_symbol_0_clk>,
			<&ufs_phy_rx_symbol_1_clk>, <&ufs_phy_tx_symbol_0_clk>,
			<&usb3_phy_wrapper_gcc_usb30_pipe_clk>;
		clock-names = "bi_tcxo", "pcie_0_pipe_clk",
			"sleep_clk", "ufs_phy_rx_symbol_0_clk",
			"ufs_phy_rx_symbol_1_clk", "ufs_phy_tx_symbol_0_clk",
			"usb3_phy_wrapper_gcc_usb30_pipe_clk";
		#clock-cells = <1>;
		#reset-cells = <1>;
	};

	gpucc: clock-controller@3d90000 {
		compatible = "qcom,cliffs-gpucc", "syscon";
		reg = <0x3d90000 0xa000>;
		reg-name = "cc_base";
		vdd_cx-supply = <&VDD_CX_LEVEL>;
		vdd_mx-supply = <&VDD_MXA_LEVEL>;
		vdd_mxc-supply = <&VDD_MXC_LEVEL>;
		clocks = <&rpmhcc RPMH_CXO_CLK>, <&rpmhcc RPMH_CXO_CLK_A>,
			<&gcc GCC_GPU_GPLL0_CLK_SRC>, <&gcc GCC_GPU_GPLL0_DIV_CLK_SRC>;
		clock-names = "bi_tcxo", "bi_tcxo_ao",
			"gpll0_out_main", "gpll0_out_main_div";
		#clock-cells = <1>;
		#reset-cells = <1>;
	};

	tcsrcc: clock-controller@1f40000 {
		compatible = "qcom,pineapple-tcsrcc", "syscon";
		reg = <0x1f40000 0xc0000>;
		reg-name = "cc_base";
		#clock-cells = <1>;
		#reset-cells = <1>;
	};

	videocc: clock-controller@aaf0000 {
		compatible = "qcom,cliffs-videocc", "syscon";
		reg = <0xaaf0000 0x10000>;
		reg-name = "cc_base";
		vdd_mm-supply = <&VDD_MM_LEVEL>;
		vdd_mxc-supply = <&VDD_MXC_LEVEL>;
		clocks = <&rpmhcc RPMH_CXO_CLK>, <&rpmhcc RPMH_CXO_CLK_A>,
			 <&sleep_clk>, <&gcc GCC_VIDEO_AHB_CLK>;
		clock-names = "bi_tcxo", "bi_tcxo_ao",
			"sleep_clk", "iface";
		#clock-cells = <1>;
		#reset-cells = <1>;
	};

	apsscc: syscon@17a80000 {
		compatible = "syscon";
		reg = <0x17a80000 0x21000>;
	};

	mccc: syscon@240ba000 {
		compatible = "syscon";
		reg = <0x240ba000 0x54>;
	};

	debugcc: clock-controller@0 {
		compatible = "qcom,cliffs-debugcc";
		qcom,apsscc = <&apsscc>;
		qcom,camcc = <&camcc>;
		qcom,dispcc = <&dispcc>;
		qcom,gcc = <&gcc>;
		qcom,gpucc = <&gpucc>;
		qcom,videocc = <&videocc>;
		qcom,mccc = <&mccc>;
		clocks = <&rpmhcc RPMH_CXO_CLK>, <&camcc 0>,
			<&dispcc 0>, <&gcc 0>,
			<&gpucc 0>, <&videocc 0>;
		clock-names = "xo_clk_src", "camcc",
			"dispcc", "gcc",
			"gpucc", "videocc";
		#clock-cells = <1>;
	};

	cpufreq_hw: qcom,cpufreq-hw {
		compatible = "qcom,cpufreq-epss";
		reg = <0x17d91000 0x1000>, <0x17d92000 0x1000>, <0x17d93000 0x1000>;
		reg-names = "freq-domain0", "freq-domain1", "freq-domain2";
		clocks = <&rpmhcc RPMH_CXO_CLK>, <&gcc GCC_GPLL0>;
		clock-names = "xo", "alternate";
		interrupts = <GIC_SPI 30 IRQ_TYPE_LEVEL_HIGH>,
			<GIC_SPI 31 IRQ_TYPE_LEVEL_HIGH>,
			<GIC_SPI 19 IRQ_TYPE_LEVEL_HIGH>;
		interrupt-names = "dcvsh0_int", "dcvsh1_int", "dcvsh2_int";
		#freq-domain-cells = <1>;
	};

	qcom,cpufreq-hw-debug {
		compatible = "qcom,cpufreq-hw-epss-debug";
		qcom,freq-hw-domain = <&cpufreq_hw 0>, <&cpufreq_hw 1>, <&cpufreq_hw 2>;
	};

	tcsr: syscon@1fc0000 {
		compatible = "syscon";
		reg = <0x1fc0000 0x30000>;
	};

	qcom,mpm2-sleep-counter@c221000 {
		compatible = "qcom,mpm2-sleep-counter";
		reg = <0xc221000 0x1000>;
		clock-frequency = <32768>;
	};

	qcom,sps {
		compatible = "qcom,msm-sps-4k";
		qcom,pipe-attr-ee;
	};

	psci {
		compatible = "arm,psci-1.0";
		method = "smc";

		CPU_PD0: cpu-pd0 {
			#power-domain-cells = <0>;
			power-domains = <&CLUSTER_PD>;
		};

		CPU_PD1: cpu-pd1 {
			#power-domain-cells = <0>;
			power-domains = <&CLUSTER_PD>;
		};

		CPU_PD2: cpu-pd2 {
			#power-domain-cells = <0>;
			power-domains = <&CLUSTER_PD>;
		};

		CPU_PD3: cpu-pd3 {
			#power-domain-cells = <0>;
			power-domains = <&CLUSTER_PD>;
		};

		CPU_PD4: cpu-pd4 {
			#power-domain-cells = <0>;
			power-domains = <&CLUSTER_PD>;
		};

		CPU_PD5: cpu-pd5 {
			#power-domain-cells = <0>;
			power-domains = <&CLUSTER_PD>;
		};

		CPU_PD6: cpu-pd6 {
			#power-domain-cells = <0>;
			power-domains = <&CLUSTER_PD>;
		};

		CPU_PD7: cpu-pd7 {
			#power-domain-cells = <0>;
			power-domains = <&CLUSTER_PD>;
		};

		CLUSTER_PD: cluster-pd {
			#power-domain-cells = <0>;
			domain-idle-states = <&CLUSTER_PWR_DN &CX_RET &APSS_OFF>;
		};
	};

	ipcc_mproc: qcom,ipcc@406000 {
		compatible = "qcom,ipcc";
		reg = <0x406000 0x1000>;
		interrupts = <GIC_SPI 229 IRQ_TYPE_LEVEL_HIGH>;
		interrupt-controller;
		#interrupt-cells = <3>;
		#mbox-cells = <2>;
	};

	aoss_qmp: power-controller@c300000 {
		compatible = "qcom,aoss-qmp";
		reg = <0xc300000 0x400>;
		interrupt-parent = <&ipcc_mproc>;
		interrupts = <IPCC_CLIENT_AOP
				IPCC_MPROC_SIGNAL_GLINK_QMP
				IRQ_TYPE_EDGE_RISING>;
		mboxes = <&ipcc_mproc IPCC_CLIENT_AOP
				IPCC_MPROC_SIGNAL_GLINK_QMP>;
		#power-domain-cells = <1>;
		#clock-cells = <0>;
	};

	qmp_aop: qcom,qmp-aop {
		compatible = "qcom,qmp-mbox";
		qcom,qmp = <&aoss_qmp>;
		label = "aop";
		#mbox-cells = <1>;
	};

	qmp_tme: qcom,qmp-tme {
		compatible = "qcom,qmp-mbox";
		qcom,remote-pid = <14>;
		mboxes = <&ipcc_mproc IPCC_CLIENT_TME
				IPCC_MPROC_SIGNAL_GLINK_QMP>;
		mbox-names = "tme_qmp";
		interrupt-parent = <&ipcc_mproc>;
		interrupts = <IPCC_CLIENT_TME
				IPCC_MPROC_SIGNAL_GLINK_QMP
				IRQ_TYPE_EDGE_RISING>;

		label = "tme";
		qcom,early-boot;
		priority = <0>;
		mbox-desc-offset = <0x0>;
		#mbox-cells = <1>;
	};

	qcom,tmecom-qmp-client {
		compatible = "qcom,tmecom-qmp-client";
		mboxes = <&qmp_tme 0>;
		mbox-names = "tmecom";
		label = "tmecom";
		depends-on-supply = <&qmp_tme>;
	};

	qcom,smp2p-adsp {
		compatible = "qcom,smp2p";
		qcom,smem = <443>, <429>;
		interrupt-parent = <&ipcc_mproc>;
		interrupts = <IPCC_CLIENT_LPASS IPCC_MPROC_SIGNAL_SMP2P
			      IRQ_TYPE_EDGE_RISING>;
		mboxes = <&ipcc_mproc IPCC_CLIENT_LPASS
			  IPCC_MPROC_SIGNAL_SMP2P>;
		qcom,local-pid = <0>;
		qcom,remote-pid = <2>;

		adsp_smp2p_out: master-kernel {
			qcom,entry-name = "master-kernel";
			#qcom,smem-state-cells = <1>;
		};

		adsp_smp2p_in: slave-kernel {
			qcom,entry-name = "slave-kernel";
			interrupt-controller;
			#interrupt-cells = <2>;
		};

		sleepstate_smp2p_out: sleepstate-out {
			qcom,entry-name = "sleepstate";
			#qcom,smem-state-cells = <1>;
		};

		sleepstate_smp2p_in: qcom,sleepstate-in {
			qcom,entry-name = "sleepstate_see";
			interrupt-controller;
			#interrupt-cells = <2>;
		};

		smp2p_rdbg2_out: qcom,smp2p-rdbg2-out {
			qcom,entry-name = "rdbg";
			#qcom,smem-state-cells = <1>;
		};

		smp2p_rdbg2_in: qcom,smp2p-rdbg2-in {
			qcom,entry-name = "rdbg";
			interrupt-controller;
			#interrupt-cells = <2>;
		};
	};

	msm_gpu: qcom,kgsl-3d0@3d00000 { };

	mmio_sram: mmio-sram@17D09400 {
		#address-cells = <2>;
		#size-cells = <2>;
		compatible = "mmio-sram";
		reg = <0x0 0x17D09400 0x0 0x400>;
		ranges = <0x0 0x0 0x0 0x17D09400 0x0 0x400>;

		cpu_scp_lpri: scmi-shmem@0 {
			compatible = "arm,scmi-shmem";
			reg = <0x0 0x17D09400 0x0 0x400>;
		};
	};

	cpucp: qcom,cpucp@17400000 {
		#address-cells = <2>;
		#size-cells = <2>;
		compatible = "qcom,cpucp";
		reg =   <0x17400000 0x10>,
			<0x17d90000 0x2000>;
		#mbox-cells = <1>;
		interrupts = <GIC_SPI 62 IRQ_TYPE_LEVEL_HIGH>;
	};

	scmi: qcom,scmi {
		#address-cells = <1>;
		#size-cells = <0>;
		compatible = "arm,scmi";
		mboxes = <&cpucp 0>;
		mbox-names = "tx";
		shmem = <&cpu_scp_lpri>;

		scmi_memlat: protocol@80 {
			reg = <0x80>;
			#clock-cells = <1>;
		};
	};

	cpucp_log: qcom,cpucp_log@d8140000 {
		compatible = "qcom,cpucp-log";
		reg = <0xd8040000 0x10000>, <0xd8050000 0x10000>;
		mboxes = <&cpucp 1>;
	};

	qcom_c1dcvs: qcom,c1dcvs {
		compatible = "qcom,c1dcvs-v2";
	};

	qcom_cpufreq_stats: qcom,cpufreq_stats {
		compatible = "qcom,cpufreq-stats-v2";
	};

	qcom_dynpf: qcom,dynpf {
		compatible = "qcom,dynpf";
	};

	qcom,smp2p-cdsp {
		compatible = "qcom,smp2p";
		qcom,smem = <94>, <432>;
		interrupt-parent = <&ipcc_mproc>;
		interrupts = <IPCC_CLIENT_CDSP IPCC_MPROC_SIGNAL_SMP2P
			      IRQ_TYPE_EDGE_RISING>;
		mboxes = <&ipcc_mproc IPCC_CLIENT_CDSP IPCC_MPROC_SIGNAL_SMP2P>;
		qcom,local-pid = <0>;
		qcom,remote-pid = <5>;

		cdsp_smp2p_out: master-kernel {
			qcom,entry-name = "master-kernel";
			#qcom,smem-state-cells = <1>;
		};

		cdsp_smp2p_in: slave-kernel {
			qcom,entry-name = "slave-kernel";
			interrupt-controller;
			#interrupt-cells = <2>;
		};

		smp2p_rdbg5_out: qcom,smp2p-rdbg5-out {
			qcom,entry-name = "rdbg";
			#qcom,smem-state-cells = <1>;
		};

		smp2p_rdbg5_in: qcom,smp2p-rdbg5-in {
			qcom,entry-name = "rdbg";
			interrupt-controller;
			#interrupt-cells = <2>;
		};
	};

	qcom,smp2p-modem {
		compatible = "qcom,smp2p";
		qcom,smem = <435>, <428>;
		interrupt-parent = <&ipcc_mproc>;
		interrupts = <IPCC_CLIENT_MPSS IPCC_MPROC_SIGNAL_SMP2P
			      IRQ_TYPE_EDGE_RISING>;
		mboxes = <&ipcc_mproc IPCC_CLIENT_MPSS IPCC_MPROC_SIGNAL_SMP2P>;
		qcom,local-pid = <0>;
		qcom,remote-pid = <1>;

		modem_smp2p_out: master-kernel {
			qcom,entry-name = "master-kernel";
			#qcom,smem-state-cells = <1>;
		};

		modem_smp2p_in: slave-kernel {
			qcom,entry-name = "slave-kernel";
			interrupt-controller;
			#interrupt-cells = <2>;
		};

		smp2p_ipa_1_out: qcom,smp2p-ipa-1-out {
			qcom,entry-name = "ipa";
			#qcom,smem-state-cells = <1>;
		};

		/* ipa - inbound entry from mss */
		smp2p_ipa_1_in: qcom,smp2p-ipa-1-in {
			qcom,entry-name = "ipa";
			interrupt-controller;
			#interrupt-cells = <2>;
		};
	};

	qcom,smp2p_sleepstate {
		compatible = "qcom,smp2p-sleepstate";
		qcom,smem-states = <&sleepstate_smp2p_out 0>;
		interrupt-parent = <&sleepstate_smp2p_in>;
		interrupts = <0 0>;
		interrupt-names = "smp2p-sleepstate-in";
	};

	qcom,smp2p-wpss {
		compatible = "qcom,smp2p";
		qcom,smem = <617>, <616>;
		interrupt-parent = <&ipcc_mproc>;
		interrupts = <IPCC_CLIENT_WPSS IPCC_MPROC_SIGNAL_SMP2P
			IRQ_TYPE_EDGE_RISING>;
		mboxes = <&ipcc_mproc IPCC_CLIENT_WPSS IPCC_MPROC_SIGNAL_SMP2P>;
		qcom,local-pid = <0>;
		qcom,remote-pid = <13>;

		wpss_smp2p_out: master-kernel {
			qcom,entry-name = "master-kernel";
			#qcom,smem-state-cells = <1>;
		};

		wpss_smp2p_in: slave-kernel {
			qcom,entry-name = "slave-kernel";
			interrupt-controller;
			#interrupt-cells = <2>;
		};
	};

	wpss_pas: remoteproc-wpss@9bb00000 {
		compatible = "qcom,cliffs-wpss-pas";
		reg = <0x9bb00000 0x10000>;
		status = "ok";

		memory-region = <&wpss_mem>;
		firmware-name = "qca6750/wpss.mdt";

		clocks = <&rpmhcc RPMH_CXO_CLK>;
		clock-names = "xo";

		cx-supply = <&VDD_CX_LEVEL>;
		cx-uV-uA = <RPMH_REGULATOR_LEVEL_TURBO 100000>;
		mx-supply = <&VDD_MXA_LEVEL>;
		mx-uV-uA = <RPMH_REGULATOR_LEVEL_TURBO 100000>;
		reg-names = "cx","mx";

		qcom,signal-aop;
		qcom,qmp = <&aoss_qmp>;

		/* Inputs from wpss */
		interrupts-extended = <&intc GIC_SPI 200 IRQ_TYPE_EDGE_RISING>,
				      <&wpss_smp2p_in 0 0>,
				      <&wpss_smp2p_in 2 0>,
				      <&wpss_smp2p_in 1 0>,
				      <&wpss_smp2p_in 3 0>,
				      <&wpss_smp2p_in 7 0>;

		interrupt-names = "wdog",
				   "fatal",
				   "handover",
				   "ready",
				   "stop-ack",
				   "shutdown-ack";

		/* Outputs to wpss */
		qcom,smem-states = <&wpss_smp2p_out 0>;
		qcom,smem-state-names = "stop";

		glink-edge {
			qcom,remote-pid = <13>;
			transport = "smem";
			mboxes = <&ipcc_mproc IPCC_CLIENT_WPSS
				  IPCC_MPROC_SIGNAL_GLINK_QMP>;
			mbox-names = "wpss_smem";
			interrupt-parent = <&ipcc_mproc>;
			interrupts = <IPCC_CLIENT_WPSS
					  IPCC_MPROC_SIGNAL_GLINK_QMP
					  IRQ_TYPE_EDGE_RISING>;

			label = "wpss";
			qcom,glink-label = "wpss";

			qcom,wpss_qrtr {
				qcom,glink-channels = "IPCRTR";
				qcom,intents = <0x800  5
						0x2000 3
						0x4400 2>;
			};

		};
	};

	adsp_sleepmon: adsp-sleepmon {
		compatible = "qcom,adsp-sleepmon";
		qcom,wait_time_lpm = <45>;
		qcom,rproc-handle = <&adsp_pas>;
	};

	adsp_pas: remoteproc-adsp@03000000 {
		compatible = "qcom,cliffs-adsp-pas";
		reg = <0x03000000 0x10000>;
		status = "ok";

		cx-supply = <&VDD_LPI_CX_LEVEL>;
		cx-uV-uA = <RPMH_REGULATOR_LEVEL_TURBO 0>;
		mx-supply = <&VDD_LPI_MX_LEVEL>;
		mx-uV-uA = <RPMH_REGULATOR_LEVEL_TURBO 0>;
		reg-names = "cx", "mx";

		clocks = <&rpmhcc RPMH_CXO_CLK>;
		clock-names = "xo";

		qcom,signal-aop;
		qcom,qmp = <&aoss_qmp>;

		interconnects = <&lpass_lpicx_noc MASTER_LPASS_PROC &mc_virt SLAVE_EBI1>,
				<&aggre2_noc MASTER_CRYPTO &mc_virt SLAVE_EBI1>;
		interconnect-names = "rproc_ddr", "crypto_ddr";

		memory-region = <&adspslpi_mem &q6_adsp_dtb_mem>;

		/* Inputs from ssc */
		interrupts-extended = <&pdc 6 IRQ_TYPE_EDGE_RISING>,
					<&adsp_smp2p_in 0 0>,
					<&adsp_smp2p_in 2 0>,
					<&adsp_smp2p_in 1 0>,
					<&adsp_smp2p_in 3 0>;

		interrupt-names = "wdog",
				"fatal",
				"handover",
				"ready",
				"stop-ack";

		/* Outputs to turing */
		qcom,smem-states = <&adsp_smp2p_out 0>;
		qcom,smem-state-names = "stop";

		glink_edge: glink-edge {
			qcom,remote-pid = <2>;
			transport = "smem";
			mboxes = <&ipcc_mproc IPCC_CLIENT_LPASS
				  IPCC_MPROC_SIGNAL_GLINK_QMP>;
			mbox-names = "adsp_smem";
			interrupt-parent = <&ipcc_mproc>;
			interrupts = <IPCC_CLIENT_LPASS
				      IPCC_MPROC_SIGNAL_GLINK_QMP
				      IRQ_TYPE_EDGE_RISING>;

			label = "adsp";
			qcom,glink-label = "lpass";

			qcom,adsp_qrtr {
				qcom,glink-channels = "IPCRTR";
				qcom,intents = <0x800  5
						0x2000 3
						0x4400 2>;

				qcom,no-wake-svc = <0x190>;
			};

			qcom,pmic_glink_rpmsg {
				qcom,glink-channels = "PMIC_RTR_ADSP_APPS";
			};

			qcom,pmic_glink_log_rpmsg {
				qcom,glink-channels = "PMIC_LOGS_ADSP_APPS";
				qcom,intents = <0x800 5
						0xc00 3
						0x2000 1>;
			};

			qcom,msm_fastrpc_rpmsg {
				compatible = "qcom,msm-fastrpc-rpmsg";
				qcom,glink-channels = "fastrpcglink-apps-dsp";
				qcom,intents = <0x64 64>;
			};
		};
	};

	modem_pas: remoteproc-mss@04080000 {
		compatible = "qcom,cliffs-modem-pas";
		reg = <0x4080000 0x10000>;
		status = "ok";

		clocks = <&rpmhcc RPMH_CXO_CLK>;
		clock-names = "xo";

		cx-supply = <&VDD_CX_LEVEL>;
		cx-uV-uA = <RPMH_REGULATOR_LEVEL_TURBO 100000>;
		mx-supply = <&VDD_MODEM_LEVEL>;
		mx-uV-uA = <RPMH_REGULATOR_LEVEL_NOM_L1 100000>;
		reg-names = "cx", "mx";

		qcom,signal-aop;
		qcom,qmp = <&aoss_qmp>;

		interconnects = <&mc_virt MASTER_LLCC &mc_virt SLAVE_EBI1>,
				<&aggre2_noc MASTER_CRYPTO &mc_virt SLAVE_EBI1>;
		interconnect-names = "rproc_ddr", "crypto_ddr";

		memory-region = <&mpss_mem &q6_mpss_dtb_mem &system_cma>;
		mpss_dsm_mem_reg = <&dsm_partition_1_mem>;

		/* Inputs from mss */
		interrupts-extended = <&intc GIC_SPI 264 IRQ_TYPE_EDGE_RISING>,
					<&modem_smp2p_in 0 0>,
					<&modem_smp2p_in 2 0>,
					<&modem_smp2p_in 1 0>,
					<&modem_smp2p_in 3 0>,
					<&modem_smp2p_in 7 0>;

		interrupt-names = "wdog",
				"fatal",
				"handover",
				"ready",
				"stop-ack",
				"shutdown-ack";

		/* Outputs to mss */
		qcom,smem-states = <&modem_smp2p_out 0>;
		qcom,smem-state-names = "stop";

		glink-edge {
			qcom,remote-pid = <1>;
			transport = "smem";
			mboxes = <&ipcc_mproc IPCC_CLIENT_MPSS
				  IPCC_MPROC_SIGNAL_GLINK_QMP>;
			mbox-names = "mpss_smem";
			interrupt-parent = <&ipcc_mproc>;
			interrupts = <IPCC_CLIENT_MPSS
				      IPCC_MPROC_SIGNAL_GLINK_QMP
				      IRQ_TYPE_EDGE_RISING>;

			label = "modem";
			qcom,glink-label = "mpss";

			qcom,modem_qrtr {
				qcom,glink-channels = "IPCRTR";
				qcom,low-latency;
				qcom,intents = <0x800  5
						0x2000 3
						0x4400 2>;
			};

			qcom,modem_ds {
				qcom,glink-channels = "DS";
				qcom,intents = <0x4000 0x2>;
			};
		};
	};

	cdsp_pas: remoteproc-cdsp@32300000 {
		compatible = "qcom,cliffs-cdsp-pas";
		reg = <0x32300000 0x10000>;
		status = "ok";

		cx-supply = <&VDD_CX_LEVEL>;
		cx-uV-uA = <RPMH_REGULATOR_LEVEL_TURBO 100000>;
		mx-supply = <&VDD_MXC_LEVEL>;
		mx-uV-uA = <RPMH_REGULATOR_LEVEL_TURBO 100000>;
		nsp-supply = <&VDD_NSP_LEVEL>;
		nsp-uV-uA = <RPMH_REGULATOR_LEVEL_TURBO 100000>;
		reg-names = "cx","mx","nsp";

		memory-region = <&cdsp_mem &q6_cdsp_dtb_mem>;
		global-sync-mem-reg = <&global_sync_mem>;

		clocks = <&rpmhcc RPMH_CXO_CLK>;
		clock-names = "xo";

		qcom,signal-aop;
		qcom,qmp = <&aoss_qmp>;

		interconnects = <&nsp_noc MASTER_CDSP_PROC &mc_virt SLAVE_EBI1>,
				<&aggre2_noc MASTER_CRYPTO &mc_virt SLAVE_EBI1>;
		interconnect-names = "rproc_ddr", "crypto_ddr";

		/* Inputs from turing */
		interrupts-extended = <&intc GIC_SPI 578 IRQ_TYPE_EDGE_RISING>,
					<&cdsp_smp2p_in 0 0>,
					<&cdsp_smp2p_in 2 0>,
					<&cdsp_smp2p_in 1 0>,
					<&cdsp_smp2p_in 3 0>;

		interrupt-names = "wdog",
				"fatal",
				"handover",
				"ready",
				"stop-ack";

		/* Outputs to turing */
		qcom,smem-states = <&cdsp_smp2p_out 0>;
		qcom,smem-state-names = "stop";

		glink-edge {
			qcom,remote-pid = <5>;
			transport = "smem";
			mboxes = <&ipcc_mproc IPCC_CLIENT_CDSP
				  IPCC_MPROC_SIGNAL_GLINK_QMP>;
			mbox-names = "cdsp_smem";
			interrupt-parent = <&ipcc_mproc>;
			interrupts = <IPCC_CLIENT_CDSP
				      IPCC_MPROC_SIGNAL_GLINK_QMP
				      IRQ_TYPE_EDGE_RISING>;

			label = "cdsp";
			qcom,glink-label = "cdsp";

			qcom,cdsp_qrtr {
				qcom,glink-channels = "IPCRTR";
				qcom,intents = <0x800  5
						0x2000 3
						0x4400 2>;
			};

			qcom,msm_cdsprm_rpmsg {
				compatible = "qcom,msm-cdsprm-rpmsg";
				qcom,glink-channels = "cdsprmglink-apps-dsp";
				qcom,intents = <0x20 12
						0xF00 12>;

				msm_cdsp_rm: qcom,msm_cdsp_rm {
					compatible = "qcom,msm-cdsp-rm";
					qcom,qos-cores = <0 1 2>;
					qcom,qos-latency-us = <70>;
					qcom,qos-maxhold-ms = <20>;
				};
			};

			qcom,msm_fastrpc_rpmsg {
				compatible = "qcom,msm-fastrpc-rpmsg";
				qcom,glink-channels = "fastrpcglink-apps-dsp";
				qcom,intents = <0x64 64>;
			};
		};
	};

	qcom,glinkpkt {
		compatible = "qcom,glinkpkt";

		qcom,glinkpkt-at-mdm0 {
			qcom,glinkpkt-edge = "mpss";
			qcom,glinkpkt-ch-name = "DS";
			qcom,glinkpkt-dev-name = "at_mdm0";
		};

		qcom,glinkpkt-apr-apps2 {
			qcom,glinkpkt-edge = "adsp";
			qcom,glinkpkt-ch-name = "apr_apps2";
			qcom,glinkpkt-dev-name = "apr_apps2";
		};

		qcom,glinkpkt-data40-cntl {
			qcom,glinkpkt-edge = "mpss";
			qcom,glinkpkt-ch-name = "DATA40_CNTL";
			qcom,glinkpkt-dev-name = "smdcntl8";
		};

		qcom,glinkpkt-data1 {
			qcom,glinkpkt-edge = "mpss";
			qcom,glinkpkt-ch-name = "DATA1";
			qcom,glinkpkt-dev-name = "smd7";
		};

		qcom,glinkpkt-data4 {
			qcom,glinkpkt-edge = "mpss";
			qcom,glinkpkt-ch-name = "DATA4";
			qcom,glinkpkt-dev-name = "smd8";
		};

		qcom,glinkpkt-data11 {
			qcom,glinkpkt-edge = "mpss";
			qcom,glinkpkt-ch-name = "DATA11";
			qcom,glinkpkt-dev-name = "smd11";
		};

		qcom,glinkpkt-qmc-dma {
			qcom,glinkpkt-edge = "mpss";
			qcom,glinkpkt-ch-name = "QMC_DMA_LINE";
			qcom,glinkpkt-dev-name = "qmc_dma";
			qcom,glinkpkt-enable-ch-close;
		};

		qcom,glinkpkt-qmc-cma {
			qcom,glinkpkt-edge = "mpss";
			qcom,glinkpkt-ch-name = "QMC_CMA_LINE";
			qcom,glinkpkt-dev-name = "qmc_cma";
			qcom,glinkpkt-enable-ch-close;
		};
	};

	qcom,glink {
		compatible = "qcom,glink";
	};

	google,debug-kinfo {
		compatible = "google,debug-kinfo";
		memory-region = <&kinfo_mem>;
	};

	vendor_hooks: qcom,cpu-vendor-hooks {
		compatible = "qcom,cpu-vendor-hooks";
	};

	logbuf: qcom,logbuf-vendor-hooks {
		compatible = "qcom,logbuf-vendor-hooks";
	};

	tcsr_mutex_block: syscon@1f40000 {
		compatible = "syscon";
		reg = <0x1f40000 0x20000>;
	};

	tcsr_mutex: hwlock {
		compatible = "qcom,tcsr-mutex";
		syscon = <&tcsr_mutex_block 0 0x1000>;
		#hwlock-cells = <1>;
	};

	qcom_tzlog: tz-log@14680720 {
		compatible = "qcom,tz-log";
		reg = <0x14680720 0x3000>;
		qcom,hyplog-enabled;
		hyplog-address-offset = <0x410>;
		hyplog-size-offset = <0x414>;
		tmecrashdump-address-offset = <0x81CA0000>;
	};

	qcom_qseecom: qseecom@c1700000 {
		compatible = "qcom,qseecom";
		memory-region = <&qseecom_mem>;
		qseecom_mem = <&qseecom_mem>;
		qseecom_ta_mem = <&qseecom_ta_mem>;
		qcom,no-user-contig-mem-support;
		qcom,hlos-num-ce-hw-instances = <1>;
		qcom,hlos-ce-hw-instance = <0>;
		qcom,qsee-ce-hw-instance = <0>;
		qcom,disk-encrypt-pipe-pair = <2>;
		qcom,no-clock-support;
		qcom,appsbl-qseecom-support;
		qcom,commonlib64-loaded-by-uefi;
		qcom,qsee-reentrancy-support = <2>;
	};

	qcom_cedev: qcedev@1de0000 {
		compatible = "qcom,qcedev";
		reg = <0x1de0000 0x20000>,
			<0x1dc4000 0x28000>;
		reg-names = "crypto-base","crypto-bam-base";
		interrupts = <GIC_SPI 272 IRQ_TYPE_LEVEL_HIGH>;
		qcom,bam-pipe-pair = <2>;
		qcom,offload-ops-support;
		qcom,bam-pipe-offload-cpb-hlos = <1>;
		qcom,bam-pipe-offload-hlos-cpb = <3>;
		qcom,bam-pipe-offload-hlos-cpb-1 = <8>;
		qcom,bam-pipe-offload-hlos-hlos = <4>;
		qcom,bam-pipe-offload-hlos-hlos-1 = <9>;
		qcom,ce-hw-instance = <0>;
		qcom,ce-device = <0>;
		qcom,ce-hw-shared;
		qcom,bam-ee = <0>;
		qcom,smmu-s1-enable;
		qcom,no-clock-support;
		interconnect-names = "data_path";
		interconnects = <&aggre2_noc MASTER_CRYPTO &mc_virt SLAVE_EBI1>;
		iommus = <&apps_smmu 0x0480 0x0>,
			<&apps_smmu 0x0481 0x0>;
		qcom,iommu-dma = "atomic";
		dma-coherent;

		qcom_cedev_ns_cb {
			compatible = "qcom,qcedev,context-bank";
			label = "ns_context";
			iommus = <&apps_smmu 0x0481 0x0>;
			dma-coherent;
		};

		qcom_cedev_s_cb {
			compatible = "qcom,qcedev,context-bank";
			label = "secure_context";
			iommus = <&apps_smmu 0x0483 0x0>;
			qcom,iommu-vmid = <0x9>;
			qcom,secure-context-bank;
			dma-coherent;
		};
	};

	qcom_rng: qrng@10c3000 {
		compatible = "qcom,msm-rng";
		reg = <0x10c3000 0x1000>;
		qcom,no-qrng-config;
		qcom,no-clock-support;
	};

	gic-interrupt-router {
		compatible = "qcom,gic-intr-routing";
		/* keep silver core only to avoid wakeup of gold cores */
		qcom,gic-class0-cpus = <0 1 2>;
		/* keep gold and gold+ cores in class1 */
		qcom,gic-class1-cpus = <3 4 5 6 7>;
	};

	qfprom: qfprom@221c8000 {
		compatible = "qcom,cliffs-qfprom", "qcom,qfprom";
		reg = <0x221c8000 0x1000>;
		#address-cells = <1>;
		#size-cells = <1>;
		read-only;
		ranges;

		feat_conf6: feat_conf6@0118 {
			reg = <0x0118 0x4>;
		};
	};

	qfprom_sys: qfprom@0 {
		compatible = "qcom,qfprom-sys";

		nvmem-cells = <&feat_conf6>;
		nvmem-cell-names = "feat_conf6";
	};

	sdhc2_opp_table: sdhc2-opp-table {
		compatible = "operating-points-v2";

		opp-100000000 {
			opp-hz = /bits/ 64 <100000000>;
			opp-peak-kBps = <160000 100000>;
			opp-avg-kBps = <50000 0>;
		};

		opp-202000000 {
			opp-hz = /bits/ 64 <202000000>;
			opp-peak-kBps = <200000 120000>;
			opp-avg-kBps = <104000 0>;
		};
	};

	sdhc_2: sdhci@8804000 {
		status = "disabled";

		compatible = "qcom,sdhci-msm-v5";

		reg = <0x08804000 0x1000>;
		reg-names = "hc";

		interrupts = <GIC_SPI 207 IRQ_TYPE_LEVEL_HIGH>,
				<GIC_SPI 223 IRQ_TYPE_LEVEL_HIGH>;
		interrupt-names = "hc_irq", "pwr_irq";

		bus-width = <4>;
		no-sdio;
		no-mmc;
		qcom,restore-after-cx-collapse;

		qcom,uses_level_shifter;

		resets = <&gcc GCC_SDCC2_BCR>;
		reset-names = "core_reset";

		clocks = <&gcc GCC_SDCC2_AHB_CLK>,
			<&gcc GCC_SDCC2_APPS_CLK>;
		clock-names = "iface", "core";

		/*
		 * DLL HSR settings. Refer go/hsr - <Target> DLL settings.
		 * Note that the DLL_CONFIG_2 value is not passed from the
		 * device tree, but it is calculated in the driver.
		 */
		qcom,dll-hsr-list = <0x0007442C 0x0 0x10
					0x090106C0 0x80040868>;

		iommus = <&apps_smmu 0x140 0x0>;
		dma-coherent;
		qcom,iommu-dma = "fastmap";

		interconnects = <&aggre1_noc MASTER_SDCC_2 &mc_virt SLAVE_EBI1>,
			      <&gem_noc MASTER_APPSS_PROC &cnoc_cfg
			      SLAVE_SDCC_2>;
		interconnect-names = "sdhc-ddr","cpu-sdhc";
		operating-points-v2 = <&sdhc2_opp_table>;

		qos0 {
			mask = <0xf8>;
			vote = <44>;
		};

		qos1 {
			mask = <0x07>;
			vote = <44>;
		};
	};

	ufsphy_mem: ufsphy_mem@1d80000 {
		reg = <0x1d80000 0x2000>;
		reg-names = "phy_mem";
		#phy-cells = <0>;

		lanes-per-direction = <2>;
		clock-names = "ref_clk_src",
			"ref_aux_clk", "qref_clk",
			"rx_sym0_mux_clk", "rx_sym1_mux_clk", "tx_sym0_mux_clk",
			"rx_sym0_phy_clk", "rx_sym1_phy_clk", "tx_sym0_phy_clk";
		clocks =<&rpmhcc RPMH_CXO_PAD_CLK>,
			<&gcc GCC_UFS_PHY_PHY_AUX_CLK>,
			<&tcsrcc TCSR_UFS_CLKREF_EN>,
			<&gcc GCC_UFS_PHY_RX_SYMBOL_0_CLK_SRC>,
			<&gcc GCC_UFS_PHY_RX_SYMBOL_1_CLK_SRC>,
			<&gcc GCC_UFS_PHY_TX_SYMBOL_0_CLK_SRC>,
			<&ufs_phy_rx_symbol_0_clk>,
			<&ufs_phy_rx_symbol_1_clk>,
			<&ufs_phy_tx_symbol_0_clk>;
		resets = <&ufshc_mem 0>;
		status = "disabled";
	};

	ice_cfg: shared_ice {
		alg1 {
			alg-name = "alg1";
			rx-alloc-percent = <60>;
			status = "disabled";
		};

		alg2 {
			alg-name = "alg2";
			status = "disabled";

		};

		alg3 {
			alg-name = "alg3";
			num-core = <28 28 15 13>;
			status = "ok";
		};
	};

	ufshc_mem: ufshc@1d84000 {
		compatible = "qcom,ufshc";
		reg = <0x1d84000 0x3000>,
			<0x1d88000 0x8000>,
			<0x1d90000 0x9000>,
			<0x1da5000 0x2000>, <0x1da4000 0x10>;
		reg-names = "ufs_mem", "ufs_ice", "ufs_ice_hwkm", "mcq_sqd", "mcq_vs";
		interrupts = <GIC_SPI 265 IRQ_TYPE_LEVEL_HIGH>;
		phys = <&ufsphy_mem>;
		phy-names = "ufsphy";
		#reset-cells = <1>;

		qcom,prime-mask = <0x80>;
		qcom,silver-mask = <0x07>;
		qcom,esi-affinity-mask = <0xf8>;

		lanes-per-direction = <2>;
		clock-names =
			"core_clk",
			"bus_aggr_clk",
			"iface_clk",
			"core_clk_unipro",
			"core_clk_ice",
			"ref_clk",
			"tx_lane0_sync_clk",
			"rx_lane0_sync_clk",
			"rx_lane1_sync_clk";
		clocks =
			<&gcc GCC_UFS_PHY_AXI_CLK>,
			<&gcc GCC_AGGRE_UFS_PHY_AXI_CLK>,
			<&gcc GCC_UFS_PHY_AHB_CLK>,
			<&gcc GCC_UFS_PHY_UNIPRO_CORE_CLK>,
			<&gcc GCC_UFS_PHY_ICE_CORE_CLK>,
			<&rpmhcc RPMH_LN_BB_CLK3>,
			<&gcc GCC_UFS_PHY_TX_SYMBOL_0_CLK>,
			<&gcc GCC_UFS_PHY_RX_SYMBOL_0_CLK>,
			<&gcc GCC_UFS_PHY_RX_SYMBOL_1_CLK>;
		freq-table-hz =
			<100000000 403000000>,
			<0 0>,
			<0 0>,
			<100000000 403000000>,
			<100000000 403000000>,
			<0 0>,
			<0 0>,
			<0 0>,
			<0 0>;

		interconnects = <&aggre1_noc MASTER_UFS_MEM &mc_virt SLAVE_EBI1>,
			<&gem_noc MASTER_APPSS_PROC &cnoc_cfg SLAVE_UFS_MEM_CFG>;
		interconnect-names = "ufs-ddr", "cpu-ufs";

		qcom,ufs-bus-bw,name = "ufshc_mem";
		qcom,ufs-bus-bw,num-cases = <30>;
		qcom,ufs-bus-bw,num-paths = <2>;
		qcom,ufs-bus-bw,vectors-KBps =
		/*
		 * During HS G3 UFS runs at nominal voltage corner, vote
		 * higher bandwidth to push other buses in the data path
		 * to run at nominal to achieve max throughput.
		 * 4GBps pushes BIMC to run at nominal.
		 * 200MBps pushes CNOC to run at nominal.
		 * Vote for half of this bandwidth for HS G3 1-lane.
		 * For max bandwidth, vote high enough to push the buses
		 * to run in turbo voltage corner.
		 */
		<0 0>, <0 0>,          /* No vote */
		<922 0>, <1000 0>,     /* PWM G1 */
		<1844 0>, <1000 0>,    /* PWM G2 */
		<3688 0>, <1000 0>,    /* PWM G3 */
		<7376 0>, <1000 0>,    /* PWM G4 */
		<14752 0>, <1000 0>,   /* PWM G5 */
		<1844 0>, <1000 0>,    /* PWM G1 L2 */
		<3688 0>, <1000 0>,    /* PWM G2 L2 */
		<7376 0>, <1000 0>,    /* PWM G3 L2 */
		<14752 0>, <1000 0>,   /* PWM G4 L2 */
		<29504 0>, <1000 0>,   /* PWM G5 L2 */
		<127796 0>, <1000 0>,  /* HS G1 RA */
		<255591 0>, <1000 0>,  /* HS G2 RA */
		<1492582 0>, <102400 0>,  /* HS G3 RA */
		<2915200 0>, <204800 0>,  /* HS G4 RA */
		<255591 0>, <1000 0>,  /* HS G1 RA L2 */
		<511181 0>, <1000 0>,  /* HS G2 RA L2 */
		<1492582 0>, <204800 0>, /* HS G3 RA L2 */
		<2915200 0>, <409600 0>, /* HS G4 RA L2 */
		<149422 0>, <1000 0>,  /* HS G1 RB */
		<298189 0>, <1000 0>,  /* HS G2 RB */
		<1492582 0>, <102400 0>,  /* HS G3 RB */
		<2915200 0>, <204800 0>,  /* HS G4 RB */
		<298189 0>, <1000 0>,  /* HS G1 RB L2 */
		<596378 0>, <1000 0>,  /* HS G2 RB L2 */
		/* As UFS working in HS G3 RB L2 mode, aggregated
		 * bandwidth (AB) should take care of providing
		 * optimum throughput requested. However, as tested,
		 * in order to scale up CNOC clock, instantaneous
		 * bindwidth (IB) needs to be given a proper value too.
		 */
		<1492582 0>, <204800 409600>, /* HS G3 RB L2 KBPs */
		<2915200 0>, <409600 409600>, /* HS G4 RB L2 */
		<5836800 0>, <819200 0>,      /* HS G5 RA L2*/
		<5836800 0>, <819200 0>,      /* HS G5 RB L2 */
		<7643136 0>, <819200 0>;      /* Max. bandwidth */

		qcom,bus-vector-names = "MIN",
		"PWM_G1_L1", "PWM_G2_L1", "PWM_G3_L1", "PWM_G4_L1", "PWM_G5_L1",
		"PWM_G1_L2", "PWM_G2_L2", "PWM_G3_L2", "PWM_G4_L2", "PWM_G5_L2",
		"HS_RA_G1_L1", "HS_RA_G2_L1", "HS_RA_G3_L1", "HS_RA_G4_L1",
		"HS_RA_G1_L2", "HS_RA_G2_L2", "HS_RA_G3_L2", "HS_RA_G4_L2",
		"HS_RB_G1_L1", "HS_RB_G2_L1", "HS_RB_G3_L1", "HS_RB_G4_L1",
		"HS_RB_G1_L2", "HS_RB_G2_L2", "HS_RB_G3_L2", "HS_RB_G4_L2",
		"HS_RA_G5_L2", "HS_RB_G5_L2",
		"MAX";

		iommus = <&apps_smmu 0x60 0x0>;
		qcom,iommu-dma = "fastmap";
		qcom,iommu-dma-addr-pool = <0x1000 0xFFFFF000>;
		qcom,iommu-msi-size = <0x1000>;
		shared-ice-cfg = <&ice_cfg>;
		dma-coherent;

		/* skip pbl wa as we have got this fixed in pbl */
		qcom,bypass-pbl-rst-wa;

		reset-gpios = <&tlmm 178 GPIO_ACTIVE_LOW>;
		resets = <&gcc GCC_UFS_PHY_BCR>;
		reset-names = "rst";

		msi-parent = <&gic_its 0x60>;
		qcom,broken-ahit-wa;

		status = "disabled";

		qos0 {
			mask = <0xf8>;
			vote = <44>;
			perf;
			cpu_freq_vote = <3 7>;
		};

		qos1 {
			mask = <0x07>;
			vote = <44>;
			cpu_freq_vote = <0>;
		};
	};

	qcom,rmtfs_sharedmem@0 {
		compatible = "qcom,sharedmem-uio";
		reg = <0x0 0x400000>;
		reg-names = "rmtfs";
		qcom,client-id = <0x00000001>;
	};

	pcie_crm_hw_0_bcm_voter: bcm_voter@0 {
		compatible = "qcom,bcm-voter";
		qcom,crm-name = "pcie_crm";
		qcom,crm-client-idx = <0>;
		qcom,crm-pwr-states = <5>;
	};

	clk_virt: interconnect@0 {
		compatible = "qcom,cliffs-clk_virt";
		#interconnect-cells = <1>;
		qcom,bcm-voter-names = "hlos", "pcie_crm_hw_0";
		qcom,bcm-voters = <&apps_bcm_voter>,
				  <&pcie_crm_hw_0_bcm_voter>;
	};

	mc_virt: interconnect@1 {
		compatible = "qcom,cliffs-mc_virt";
		#interconnect-cells = <1>;
		qcom,bcm-voter-names = "hlos",
					"disp",
					"cam_ife_0",
					"cam_ife_1",
					"cam_ife_2",
					"pcie_crm_hw_0";
		qcom,bcm-voters = <&apps_bcm_voter>,
				  <&disp_bcm_voter>,
				  <&cam_bcm_voter0>,
				  <&cam_bcm_voter1>,
				  <&cam_bcm_voter2>,
				  <&pcie_crm_hw_0_bcm_voter>;
	};

	aggre1_noc: interconnect@16E0000 {
		compatible = "qcom,cliffs-aggre1_noc";
		reg = <0x016E0000 0x19180>;
		#interconnect-cells = <1>;
		qcom,bcm-voter-names = "hlos";
		qcom,bcm-voters = <&apps_bcm_voter>;
		clocks =  <&gcc GCC_AGGRE_UFS_PHY_AXI_CLK>,
			 <&gcc GCC_AGGRE_USB3_PRIM_AXI_CLK>;
	};

	aggre2_noc: interconnect@1700000 {
		compatible = "qcom,cliffs-aggre2_noc";
		reg = <0x01700000 0x1E500>;
		#interconnect-cells = <1>;
		qcom,bcm-voter-names = "hlos";
		qcom,bcm-voters = <&apps_bcm_voter>;
		clocks = <&rpmhcc RPMH_IPA_CLK>;
	};

	cnoc_cfg: interconnect@1600000 {
		compatible = "qcom,cliffs-cnoc_cfg";
		reg = <0x01600000 0x6900>;
		#interconnect-cells = <1>;
		qcom,bcm-voter-names = "hlos";
		qcom,bcm-voters = <&apps_bcm_voter>;
	};

	cnoc_main: interconnect@1500000 {
		compatible = "qcom,cliffs-cnoc_main";
		reg = <0x01500000 0x14400>;
		#interconnect-cells = <1>;
		qcom,bcm-voter-names = "hlos";
		qcom,bcm-voters = <&apps_bcm_voter>;
	};

	gem_noc: interconnect@24100000 {
		compatible = "qcom,cliffs-gem_noc";
		reg = <0x24100000 0xC3080>;
		#interconnect-cells = <1>;
		qcom,bcm-voter-names = "hlos",
					"disp",
					"cam_ife_0",
					"cam_ife_1",
					"cam_ife_2",
					"pcie_crm_hw_0";
		qcom,bcm-voters = <&apps_bcm_voter>,
				  <&disp_bcm_voter>,
				  <&cam_bcm_voter0>,
				  <&cam_bcm_voter1>,
				  <&cam_bcm_voter2>,
				  <&pcie_crm_hw_0_bcm_voter>;
	};

	lpass_ag_noc: interconnect@7E40000 {
		compatible = "qcom,cliffs-lpass_ag_noc";
		reg = <0x07E40000 0xE080>;
		#interconnect-cells = <1>;
		qcom,bcm-voter-names = "hlos";
		qcom,bcm-voters = <&apps_bcm_voter>;
	};

	lpass_lpiaon_noc: interconnect@7400000 {
		compatible = "qcom,cliffs-lpass_lpiaon_noc";
		reg = <0x07400000 0x19080>;
		#interconnect-cells = <1>;
		qcom,bcm-voter-names = "hlos";
		qcom,bcm-voters = <&apps_bcm_voter>;
	};

	lpass_lpicx_noc: interconnect@7430000 {
		compatible = "qcom,cliffs-lpass_lpicx_noc";
		reg = <0x07430000 0x3A200>;
		#interconnect-cells = <1>;
		qcom,bcm-voter-names = "hlos";
		qcom,bcm-voters = <&apps_bcm_voter>;
	};

	mmss_noc: interconnect@1400000 {
		compatible = "qcom,cliffs-mmss_noc";
		reg = <0x1400000 0xDC000>;
		#interconnect-cells = <1>;
		qcom,bcm-voter-names = "hlos",
				       "disp",
				       "cam_ife_0",
				       "cam_ife_1",
				       "cam_ife_2";
		qcom,bcm-voters = <&apps_bcm_voter>,
				  <&disp_bcm_voter>,
				  <&cam_bcm_voter0>,
				  <&cam_bcm_voter1>,
				  <&cam_bcm_voter2>;
	};

	nsp_noc: interconnect@320C0000 {
		compatible = "qcom,cliffs-nsp_noc";
		reg = <0x320C0000 0xE080>;
		#interconnect-cells = <1>;
		qcom,bcm-voter-names = "hlos";
		qcom,bcm-voters = <&apps_bcm_voter>;
	};

	pcie_anoc: interconnect@16C0000 {
		compatible = "qcom,cliffs-pcie_anoc";
		reg = <0x016C0000 0x12400>;
		#interconnect-cells = <1>;
		qcom,bcm-voter-names = "hlos", "pcie_crm_hw_0";
		qcom,bcm-voters = <&apps_bcm_voter>,
				  <&pcie_crm_hw_0_bcm_voter>;
		clocks = <&gcc GCC_AGGRE_NOC_PCIE_AXI_CLK>,
			 <&gcc GCC_CFG_NOC_PCIE_ANOC_AHB_CLK>;
	};

	system_noc: interconnect@1680000 {
		compatible = "qcom,cliffs-system_noc";
		reg = <0x01680000 0x40000>;
		#interconnect-cells = <1>;
		qcom,bcm-voter-names = "hlos";
		qcom,bcm-voters = <&apps_bcm_voter>;
	};

	qcom,secure-buffer {
		compatible = "qcom,secure-buffer";
		qcom,vmid-cp-camera-preview-ro;
	};

	qcom,mem-buf {
		compatible = "qcom,mem-buf";
		qcom,mem-buf-capabilities = "supplier";
		qcom,vmid = <3>;
	};

	qcom,hdcp {
		compatible = "qcom,hdcp";
		qcom,use-smcinvoke = <1>;
	};

	qcom,mem-buf-msgq {
		compatible = "qcom,mem-buf-msgq";
	};

	qti,smmu-proxy {
		compatible = "smmu-proxy-sender";
	};

	eud: qcom,msm-eud@88e0000 {
		compatible = "qcom,msm-eud";
		interrupt-names = "eud_irq";
		interrupt-parent = <&pdc>;
		interrupts = <11 IRQ_TYPE_LEVEL_HIGH>;
		reg = <0x088E0000 0x2000>,
		      <0x088E2000 0x1000>;
		reg-names = "eud_base", "eud_mode_mgr2";
		qcom,secure-eud-en;
		qcom,eud-utmi-delay = /bits/ 16 <255>;
		status = "ok";
	};

	llcc_pmu: llcc-pmu@24095000 {
		compatible = "qcom,llcc-pmu-ver2";
		reg = <0x24095000 0x300>;
		reg-names = "lagg-base";
	};

	qcom_pmu: qcom,pmu {
		compatible = "qcom,pmu";
		qcom,long-counter;
		qcom,pmu-events-tbl =
			< 0x0008 0xFF 0x02 0xFF >,
			< 0x0011 0xFF 0x01 0xFF >,
			< 0x0017 0xFF 0xFF 0xFF >,
			< 0x0037 0xFF 0xFF 0xFF >,
			< 0x1000 0xFF 0xFF 0xFF >;
	};

	ddr_freq_table: ddr-freq-table {
		qcom,freq-tbl =
			<  547000 >,
			<  768000 >,
			< 1555000 >,
			< 1708000 >,
			< 2092000 >,
			< 2736000 >,
			< 3187000 >,
			< 3686000 >,
			< 4224000 >;
	};

	llcc_freq_table: llcc-freq-table {
		qcom,freq-tbl =
			<  300000 >,
			<  466500 >,
			<  600000 >,
			<  806000 >,
			<  933000 >,
			< 1066000 >;
	};

	ddrqos_freq_table: ddrqos-freq-table {
		qcom,freq-tbl =
			< 0 >,
			< 1 >;
	};

	qcom_dcvs: qcom,dcvs {
		compatible = "qcom,dcvs";
		#address-cells = <1>;
		#size-cells = <1>;
		ranges;

		qcom_l3_dcvs_hw: l3 {
			compatible = "qcom,dcvs-hw";
			qcom,dcvs-hw-type = <2>;
			qcom,bus-width = <32>;
			reg = <0x17d90000 0x4000>, <0x17d90100 0xa0>;
			reg-names = "l3-base", "l3tbl-base";

			l3_dcvs_sp: sp {
				compatible = "qcom,dcvs-path";
				qcom,dcvs-path-type = <0>;
				qcom,shared-offset = <0x0090>;
			};
		};

		qcom_ddr_dcvs_hw: ddr {
			compatible = "qcom,dcvs-hw";
			qcom,dcvs-hw-type = <0>;
			qcom,bus-width = <4>;
			qcom,freq-tbl = <&ddr_freq_table>;

			ddr_dcvs_sp: sp {
				compatible = "qcom,dcvs-path";
				qcom,dcvs-path-type = <0>;
				interconnects = <&mc_virt MASTER_LLCC
						 &mc_virt SLAVE_EBI1>;
			};

			ddr_dcvs_fp: fp {
				compatible = "qcom,dcvs-path";
				qcom,dcvs-path-type = <1>;
				qcom,fp-voter = <&dcvs_fp>;
			};
		};

		qcom_llcc_dcvs_hw: llcc {
			compatible = "qcom,dcvs-hw";
			qcom,dcvs-hw-type = <1>;
			qcom,bus-width = <16>;
			qcom,freq-tbl = <&llcc_freq_table>;

			llcc_dcvs_sp: sp {
				compatible = "qcom,dcvs-path";
				qcom,dcvs-path-type = <0>;
				interconnects = <&gem_noc MASTER_APPSS_PROC
						 &gem_noc SLAVE_LLCC>;
			};

			llcc_dcvs_fp: fp {
				compatible = "qcom,dcvs-path";
				qcom,dcvs-path-type = <1>;
				qcom,fp-voter = <&dcvs_fp>;
			};
		};

		qcom_ddrqos_dcvs_hw: ddrqos {
			compatible = "qcom,dcvs-hw";
			qcom,dcvs-hw-type = <3>;
			qcom,bus-width = <1>;
			qcom,freq-tbl = <&ddrqos_freq_table>;

			ddrqos_dcvs_sp: sp {
				compatible = "qcom,dcvs-path";
				qcom,dcvs-path-type = <0>;
				interconnects = <&mc_virt MASTER_LLCC
						 &mc_virt SLAVE_EBI1>;
			};
		};
	};

	qcom_scmi_plh: qcom,scmi_plh {
		compatible = "qcom,scmi_plh";
	};

	qcom_memlat: qcom,memlat {
		compatible = "qcom,memlat";

		ddr {
			compatible = "qcom,memlat-grp";
			qcom,target-dev = <&qcom_ddr_dcvs_hw>;
			qcom,sampling-path = <&ddr_dcvs_fp>;
			qcom,miss-ev = <0x1000>;

			silver {
				compatible = "qcom,memlat-mon";
				qcom,cpulist = <&CPU0 &CPU1 &CPU2>;
				qcom,cpufreq-memfreq-tbl =
					< 1113600  547000 >,
					< 1478400  768000 >,
					< 1843200 1555000 >;
				qcom,sampling-enabled;
			};

			gold {
				compatible = "qcom,memlat-mon";
				qcom,cpulist = <&CPU3 &CPU4 &CPU5 &CPU6>;
				qcom,cpufreq-memfreq-tbl =
					<  633600  547000 >,
					< 1190400 1555000 >,
					< 1401600 1708000 >,
					< 1824000 2736000 >,
					< 2572800 3686000 >,
					< 2611200 4224000 >;
				qcom,sampling-enabled;
			};

			prime {
				compatible = "qcom,memlat-mon";
				qcom,cpulist = <&CPU7>;
				qcom,cpufreq-memfreq-tbl =
					<  633600  547000 >,
					<  960000  768000 >,
					< 1209600 1555000 >,
					< 1459200 1708000 >,
					< 2150400 2736000 >,
					< 2668800 3686000 >,
					< 2800000 4224000 >;
				qcom,sampling-enabled;
			};

			gold-compute {
				compatible = "qcom,memlat-mon";
				qcom,cpulist = <&CPU3 &CPU4 &CPU5 &CPU6 &CPU7>;
				qcom,cpufreq-memfreq-tbl =
					<  940800  547000 >,
					< 1190400  768000 >,
					< 1824000 1708000 >,
					< 2361600 2092000 >,
					< 2707200 2736000 >;
				qcom,sampling-enabled;
				qcom,compute-mon;
			};

			prime-latfloor {
				compatible = "qcom,memlat-mon";
				qcom,cpulist = <&CPU7>;
				qcom,cpufreq-memfreq-tbl =
					< 2150400  547000 >,
					< 2457600 4224000 >;
				qcom,sampling-enabled;
			};
		};

		llcc {
			compatible = "qcom,memlat-grp";
			qcom,target-dev = <&qcom_llcc_dcvs_hw>;
			qcom,sampling-path = <&llcc_dcvs_fp>;
			qcom,miss-ev = <0x37>;

			silver {
				compatible = "qcom,memlat-mon";
				qcom,cpulist = <&CPU0 &CPU1 &CPU2>;
				qcom,cpufreq-memfreq-tbl =
					<  902400  300000 >,
					< 1478400  466500 >,
					< 1843200  600000 >;
				qcom,sampling-enabled;
			};

			gold {
				compatible = "qcom,memlat-mon";
				qcom,cpulist = <&CPU3 &CPU4 &CPU5 &CPU6 &CPU7>;
				qcom,cpufreq-memfreq-tbl =
					<  633600  300000 >,
					< 1190400  466500 >,
					< 1401600  600000 >,
					< 1824000  806000 >,
					< 2361600  933000 >,
					< 2707200 1066000 >;
				qcom,sampling-enabled;
			};

			gold-compute {
				compatible = "qcom,memlat-mon";
				qcom,cpulist = <&CPU3 &CPU4 &CPU5 &CPU6 &CPU7>;
				qcom,cpufreq-memfreq-tbl =
					< 2073600  300000 >,
					< 2361600  600000 >;
				qcom,sampling-enabled;
				qcom,compute-mon;
			};
		};

		l3 {
			compatible = "qcom,memlat-grp";
			qcom,target-dev = <&qcom_l3_dcvs_hw>;
			qcom,sampling-path = <&l3_dcvs_sp>;
			qcom,miss-ev = <0x17>;

			silver {
				compatible = "qcom,memlat-mon";
				qcom,cpulist = <&CPU0 &CPU1 &CPU2>;
				qcom,cpufreq-memfreq-tbl =
					<  307200  364800 >,
					<  595200  518400 >,
					<  787200  614400 >,
					<  902400  806400 >,
					< 1017600  902400 >,
					< 1113600  998400 >,
					< 1228800 1094400 >,
					< 1344000 1209600 >,
					< 1478400 1344000 >,
					< 1593600 1497600 >,
					< 1843200 1593600 >,
					< 2054400 1804800 >;
				qcom,sampling-enabled;
			};

			gold {
				compatible = "qcom,memlat-mon";
				qcom,cpulist = <&CPU3 &CPU4 &CPU5 &CPU6>;
				qcom,cpufreq-memfreq-tbl =
					<  480000  364800 >,
					<  633600  518400 >,
					<  940800  806400 >,
					< 1190400  902400 >,
					< 1286400  998400 >,
					< 1497600 1209600 >,
					< 1708800 1344000 >,
					< 2073600 1497600 >,
					< 2361000 1593600 >,
					< 2707200 1804800 >;
				qcom,sampling-enabled;
			};

			prime {
				compatible = "qcom,memlat-mon";
				qcom,cpulist = <&CPU7>;
				qcom,cpufreq-memfreq-tbl =
					<  480000  364800 >,
					<  633600  518400 >,
					<  960000  806400 >,
					< 1324800  998400 >,
					< 1651200 1209600 >,
					< 1766400 1344000 >,
					< 2150400 1497600 >,
					< 2457600 1593600 >,
					< 2880000 1804800 >;
				qcom,sampling-enabled;
			};

			prime-compute {
				compatible = "qcom,memlat-mon";
				qcom,cpulist = <&CPU7>;
				qcom,cpufreq-memfreq-tbl =
					< 2150400  364800 >,
					< 2880000 1804800 >;
				qcom,sampling-enabled;
				qcom,compute-mon;
			};
		};

		ddrqos {
			compatible = "qcom,memlat-grp";
			qcom,target-dev = <&qcom_ddrqos_dcvs_hw>;
			qcom,sampling-path = <&ddrqos_dcvs_sp>;
			qcom,miss-ev = <0x1000>;

			ddrqos_gold_lat: gold {
				compatible = "qcom,memlat-mon";
				qcom,cpulist = <&CPU3 &CPU4 &CPU5 &CPU6 &CPU7>;
				qcom,cpufreq-memfreq-tbl =
					< 2188800 0 >,
					< 2707200 1 >;
				qcom,sampling-enabled;
			};

			ddrqos_prime_lat: prime {
				compatible = "qcom,memlat-mon";
				qcom,cpulist = <&CPU7>;
				qcom,cpufreq-memfreq-tbl =
					< 1459200 0 >,
					< 2880000 1 >;
				qcom,sampling-enabled;
			};

			ddrqos_prime_latfloor: prime-latfloor {
				compatible = "qcom,memlat-mon";
				qcom,cpulist = <&CPU7>;
				qcom,cpufreq-memfreq-tbl =
					< 2150400 0 >,
					< 2880000 1 >;
				qcom,sampling-enabled;
			};
		};
	};

	qcom_llcc_l3_vote: qcom,llcc-l3-vote {
		qcom,target-dev = <&qcom_l3_dcvs_hw>;
		qcom,secondary-map =
			<  300000  364800>,
			<  466500  518400>,
			<  600000  614400 >,
			<  806000  806400 >,
			<  933000  902400>,
			< 1066000  998400>;
	};

	bwmon_llcc: qcom,bwmon-llcc@240B7300 {
		compatible = "qcom,bwmon4";
		reg = <0x240B7400 0x300>, <0x240B7300 0x200>;
		reg-names = "base", "global_base";
		interrupts = <GIC_SPI 581 IRQ_TYPE_LEVEL_HIGH>;
		qcom,mport = <0>;
		qcom,hw-timer-hz = <19200000>;
		qcom,count-unit = <0x10000>;
		qcom,target-dev = <&qcom_llcc_dcvs_hw>;
		qcom,second-vote = <&qcom_llcc_l3_vote>;
	};

	bwmon_ddr: qcom,bwmon-ddr@24091000 {
		compatible = "qcom,bwmon5";
		reg = <0x24091000 0x1000>;
		reg-names = "base";
		interrupts = <GIC_SPI 81 IRQ_TYPE_LEVEL_HIGH>;
		qcom,hw-timer-hz = <19200000>;
		qcom,count-unit = <0x10000>;
		qcom,target-dev = <&qcom_ddr_dcvs_hw>;
	};

	qcom,pmic_glink {
		compatible = "qcom,pmic-glink";
		qcom,pmic-glink-channel = "PMIC_RTR_ADSP_APPS";
		qcom,subsys-name = "lpass";
		qcom,protection-domain = "tms/servreg", "msm/adsp/charger_pd";
		depends-on-supply = <&ipcc_mproc>;

		battery_charger: qcom,battery_charger {
			compatible = "qcom,battery-charger";
		};

		ucsi: qcom,ucsi {
			compatible = "qcom,ucsi-glink";
		};

		altmode: qcom,altmode {
			compatible = "qcom,altmode-glink";
			#altmode-cells = <1>;
		};
	};

	qcom,pmic_glink_log {
		compatible = "qcom,pmic-glink";
		qcom,pmic-glink-channel = "PMIC_LOGS_ADSP_APPS";

		qcom,battery_debug {
			compatible = "qcom,battery-debug";
		};

		qcom,charger_ulog_glink {
			compatible = "qcom,charger-ulog-glink";
		};

		pmic_glink_debug: qcom,pmic_glink_debug {
			compatible = "qcom,pmic-glink-debug";
			#address-cells = <1>;
			#size-cells = <0>;
			depends-on-supply = <&spmi1_bus>;
		};

		pmic_glink_adc: qcom,glink-adc {
			compatible = "qcom,glink-adc";
			#address-cells = <1>;
			#size-cells = <0>;
			#io-channel-cells = <1>;
			status = "disabled";
		};
	};
};

&reserved_memory {
	#address-cells = <2>;
	#size-cells = <2>;
	ranges;

	cdsp_eva_mem: cdsp_eva_region {
		compatible = "shared-dma-pool";
		alloc-ranges = <0x0 0x00000000 0x0 0xffffffff>;
		reusable;
		alignment = <0x0 0x400000>;
		size = <0x0 0x400000>;
	};

	/* global autoconfigured region for contiguous allocations */
	system_cma: linux,cma {
		compatible = "shared-dma-pool";
		alloc-ranges = <0x0 0x00000000 0x0 0xffffffff>;
		reusable;
		alignment = <0x0 0x400000>;
		size = <0x0 0x2000000>;
		linux,cma-default;
	};

	adsp_mem_heap: adsp_heap_region {
		compatible = "shared-dma-pool";
		alloc-ranges = <0x0 0x00000000 0x0 0xffffffff>;
		reusable;
		alignment = <0x0 0x400000>;
		size = <0x0 0xC00000>;
	};

	cdsp_secure_heap_cma: secure_cdsp_region { /* Secure DSP */
		compatible = "shared-dma-pool";
		alloc-ranges = <0x0 0x00000000 0x0 0xffffffff>;
		reusable;
		alignment = <0x0 0x400000>;
		size = <0x0 0x2800000>;
	};

	qseecom_mem: qseecom_region {
		compatible = "shared-dma-pool";
		alloc-ranges = <0x0 0x00000000 0x0 0xffffffff>;
		reusable;
		alignment = <0x0 0x400000>;
		size = <0x0 0x1800000>;
	};

	qseecom_ta_mem: qseecom_ta_region {
		compatible = "shared-dma-pool";
		alloc-ranges = <0x0 0x00000000 0x0 0xffffffff>;
		reusable;
		alignment = <0x0 0x400000>;
		size = <0x0 0x3400000>;
	};

	kinfo_mem: debug_kinfo_region {
		alloc-ranges = <0x0 0x00000000 0xffffffff 0xffffffff>;
		size = <0x0 0x1000>;
		no-map;
	};

	non_secure_display_memory: non_secure_display_region {
		compatible = "shared-dma-pool";
		reusable;
		alloc-ranges = <0x0 0x00000000 0x0 0xffffffff>;
		size = <0x0 0xa400000>;
		alignment = <0x0 0x400000>;
	};

        ramoops_mem: ramoops_region {
		compatible = "ramoops";
		reg = <0x0 0xa7000000 0x0 0x400000>;
		console-size = <0x200000>;
		pmsg-size = <0x200000>;
		mem-type = <2>;
	};

	va_md_mem: va_md_mem_region {
		compatible = "shared-dma-pool";
		alloc-ranges = <0x0 0x00000000 0x0 0xffffffff>;
		reusable;
		size = <0 0x1000000>;
	};
};

&firmware {
	qcom_scm {
		compatible = "qcom,scm";
		qcom,dload-mode = <&tcsr 0x19000>;
	};

	qcom_smcinvoke {
		compatible = "qcom,smcinvoke";
	};

	qtee_shmbridge {
		compatible = "qcom,tee-shared-memory-bridge";
	};
};

#include "cliffs-regulators.dtsi"
#include "cliffs-pinctrl.dtsi"
#include "cliffs-reserved-memory.dtsi"
#include "msm-arm-smmu-cliffs.dtsi"
#include "cliffs-dma-heaps.dtsi"
#include "pineapple-gdsc.dtsi"
#include "ipcc-test.dtsi"
#include "cliffs-usb.dtsi"
#include "cliffs-qupv3.dtsi"
#include "cliffs-pcie.dtsi"
#include "msm-rdbg.dtsi"

&qupv3_se0_i2c {
	status = "ok";
	wcd_usbss: wcd939x_i2c@e {
		compatible = "qcom,wcd939x-i2c";
		reg = <0xe>;
		vdd-usb-cp-supply = <&L7B>;
	};
};

&cam_cc_bps_gdsc {
	clocks = <&gcc GCC_CAMERA_AHB_CLK>;
	clock-names = "ahb_clk";
	parent-supply = <&cam_cc_titan_top_gdsc>;
	status = "ok";
};

&cam_cc_ife_0_gdsc {
	clocks = <&gcc GCC_CAMERA_AHB_CLK>;
	clock-names = "ahb_clk";
	parent-supply = <&cam_cc_titan_top_gdsc>;
	status = "ok";
};

&cam_cc_ife_1_gdsc {
	clocks = <&gcc GCC_CAMERA_AHB_CLK>;
	clock-names = "ahb_clk";
	parent-supply = <&cam_cc_titan_top_gdsc>;
	status = "ok";
};

&cam_cc_ife_2_gdsc {
	clocks = <&gcc GCC_CAMERA_AHB_CLK>;
	clock-names = "ahb_clk";
	parent-supply = <&cam_cc_titan_top_gdsc>;
	status = "ok";
};

&cam_cc_ipe_0_gdsc {
	clocks = <&gcc GCC_CAMERA_AHB_CLK>;
	clock-names = "ahb_clk";
	parent-supply = <&cam_cc_titan_top_gdsc>;
	status = "ok";
};

&cam_cc_sfe_0_gdsc {
	clocks = <&gcc GCC_CAMERA_AHB_CLK>;
	clock-names = "ahb_clk";
	parent-supply = <&cam_cc_titan_top_gdsc>;
	status = "ok";
};

&cam_cc_sfe_1_gdsc {
	clocks = <&gcc GCC_CAMERA_AHB_CLK>;
	clock-names = "ahb_clk";
	parent-supply = <&cam_cc_titan_top_gdsc>;
	status = "ok";
};

&cam_cc_titan_top_gdsc {
	clocks = <&gcc GCC_CAMERA_AHB_CLK>;
	clock-names = "ahb_clk";
	interconnects = <&mmss_noc MASTER_CAMNOC_HF &mmss_noc SLAVE_MNOC_HF_MEM_NOC>;
	interconnect-names = "mmnoc";
	parent-supply = <&VDD_MM_MXC_VOTER_LEVEL>;
	status = "ok";
};

&disp_cc_mdss_core_gdsc {
	clocks = <&gcc GCC_DISP_AHB_CLK>;
	clock-names = "ahb_clk";
	parent-supply = <&VDD_MM_LEVEL>;
	status = "ok";
};

&disp_cc_mdss_core_int2_gdsc {
	clocks = <&gcc GCC_DISP_AHB_CLK>;
	clock-names = "ahb_clk";
	parent-supply = <&VDD_MM_LEVEL>;
	status = "ok";
};

&gcc_pcie_0_gdsc {
	parent-supply = <&VDD_CX_LEVEL>;
	status = "ok";
};

&gcc_pcie_0_phy_gdsc {
	parent-supply = <&VDD_MXA_LEVEL>;
	qcom,collapse-vote = <&gcc_apcs_gdsc_vote_ctrl 1>;
	status = "ok";
};

&gcc_ufs_mem_phy_gdsc {
	parent-supply = <&VDD_MXA_LEVEL>;
	status = "ok";
};

&gcc_ufs_phy_gdsc {
	parent-supply = <&VDD_CX_LEVEL>;
	status = "ok";
};

&gcc_usb30_prim_gdsc {
	parent-supply = <&VDD_CX_LEVEL>;
	status = "ok";
};

&gcc_usb3_phy_gdsc {
	parent-supply = <&VDD_MXA_LEVEL>;
	status = "ok";
};

&gpu_cc_cx_gdsc_hw_ctrl {
	reg = <0x3d990a0 0x4>;
};

&gpu_cc_cx_gdsc {
	reg = <0x3d9908c 0x4>;
	clocks = <&gcc GCC_GPU_CFG_AHB_CLK>;
	clock-names = "ahb_clk";
	parent-supply = <&VDD_CX_LEVEL>;
	status = "ok";
};

&gpu_cc_gx_sw_reset {
	reg = <0x3d99030 0x4>;
	status = "ok";
};

&gpu_cc_gx_acd_reset {
	reg = <0x3d99180 0x4>;
	status = "ok";
};

&gpu_cc_gx_gdsc {
	reg = <0x3d99034 0x4>;
	clocks = <&gcc GCC_GPU_CFG_AHB_CLK>;
	clock-names = "ahb_clk";
	parent-supply = <&VDD_GFX_MXC_VOTER_LEVEL>;
	status = "ok";
};

&video_cc_mvs0_gdsc {
	clocks = <&gcc GCC_VIDEO_AHB_CLK>;
	clock-names = "ahb_clk";
	parent-supply = <&video_cc_mvs0c_gdsc>;
	status = "ok";
};

&video_cc_mvs0c_gdsc {
	clocks = <&gcc GCC_VIDEO_AHB_CLK>;
	clock-names = "ahb_clk";
	parent-supply = <&VDD_MM_MXC_VOTER_LEVEL>;
	status = "ok";
};

&video_cc_mvs1_gdsc {
	clocks = <&gcc GCC_VIDEO_AHB_CLK>;
	clock-names = "ahb_clk";
	parent-supply = <&video_cc_mvs1c_gdsc>;
	status = "ok";
};

&video_cc_mvs1c_gdsc {
	clocks = <&gcc GCC_VIDEO_AHB_CLK>;
	clock-names = "ahb_clk";
	parent-supply = <&VDD_MM_MXC_VOTER_LEVEL>;
	status = "ok";
};

&qupv3_se5_2uart {
	status = "ok";
};

#include "cliffs-thermal.dtsi"
